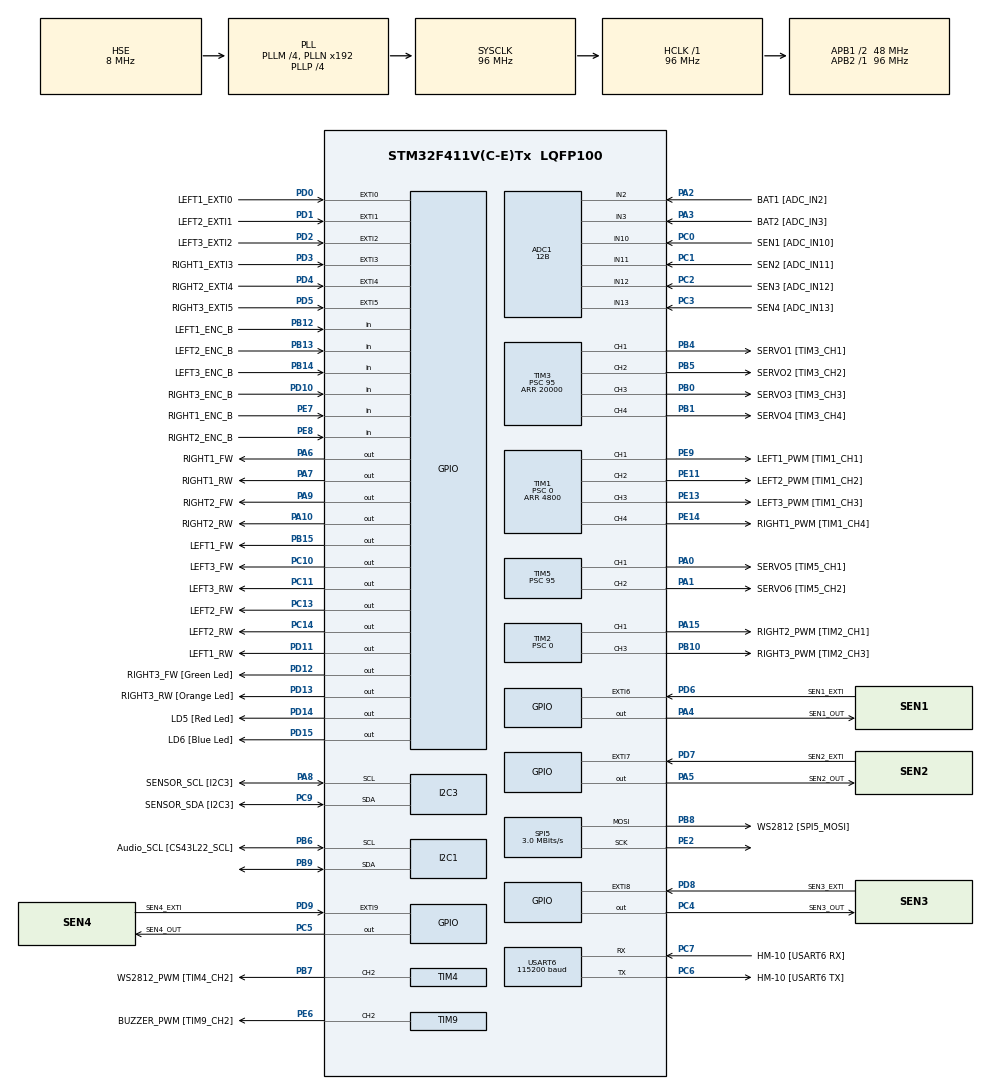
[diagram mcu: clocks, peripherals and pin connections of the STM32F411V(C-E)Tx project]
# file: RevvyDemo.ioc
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ADC1.Channel-4\#ChannelRegularConversion=ADC_CHANNEL_2
ADC1.Channel-5\#ChannelRegularConversion=ADC_CHANNEL_3
ADC1.Channel-6\#ChannelRegularConversion=ADC_CHANNEL_10
ADC1.Channel-7\#ChannelRegularConversion=ADC_CHANNEL_11
ADC1.Channel-8\#ChannelRegularConversion=ADC_CHANNEL_12
ADC1.Channel-9\#ChannelRegularConversion=ADC_CHANNEL_13
ADC1.ClockPrescaler=ADC_CLOCK_SYNC_PCLK_DIV4
ADC1.ContinuousConvMode=ENABLE
ADC1.DMAContinuousRequests=ENABLE
ADC1.DataAlign=ADC_DATAALIGN_RIGHT
ADC1.DiscontinuousConvMode=DISABLE
ADC1.EOCSelection=ADC_EOC_SINGLE_CONV
ADC1.EnableAnalogWatchDog=false
ADC1.ExternalTrigConv=ADC_SOFTWARE_START
ADC1.ExternalTrigConvEdge=ADC_EXTERNALTRIGCONVEDGE_NONE
ADC1.InjNumberOfConversion=0
ADC1.NbrOfConversion=6
ADC1.NbrOfConversionFlag=1
ADC1.Rank-4\#ChannelRegularConversion=1
ADC1.Rank-5\#ChannelRegularConversion=2
ADC1.Rank-6\#ChannelRegularConversion=3
ADC1.Rank-7\#ChannelRegularConversion=4
ADC1.Rank-8\#ChannelRegularConversion=5
ADC1.Rank-9\#ChannelRegularConversion=6
ADC1.Resolution=ADC_RESOLUTION_12B
ADC1.SamplingTime-4\#ChannelRegularConversion=ADC_SAMPLETIME_480CYCLES
ADC1.SamplingTime-5\#ChannelRegularConversion=ADC_SAMPLETIME_480CYCLES
ADC1.SamplingTime-6\#ChannelRegularConversion=ADC_SAMPLETIME_480CYCLES
ADC1.SamplingTime-7\#ChannelRegularConversion=ADC_SAMPLETIME_480CYCLES
ADC1.SamplingTime-8\#ChannelRegularConversion=ADC_SAMPLETIME_480CYCLES
ADC1.SamplingTime-9\#ChannelRegularConversion=ADC_SAMPLETIME_480CYCLES
ADC1.ScanConvMode=ENABLE
ADC1.master=1
Dma.ADC1.0.Direction=DMA_PERIPH_TO_MEMORY
Dma.ADC1.0.FIFOMode=DMA_FIFOMODE_DISABLE
Dma.ADC1.0.Instance=DMA2_Stream4
Dma.ADC1.0.MemDataAlignment=DMA_MDATAALIGN_WORD
Dma.ADC1.0.MemInc=DMA_MINC_ENABLE
Dma.ADC1.0.Mode=DMA_CIRCULAR
Dma.ADC1.0.PeriphDataAlignment=DMA_PDATAALIGN_WORD
Dma.ADC1.0.PeriphInc=DMA_PINC_DISABLE
Dma.ADC1.0.Priority=DMA_PRIORITY_LOW
Dma.Request0=ADC1
Dma.Request1=TIM4_CH2
Dma.Request2=SPI5_TX
Dma.SPI5_TX.2.Direction=DMA_MEMORY_TO_PERIPH
Dma.SPI5_TX.2.FIFOMode=DMA_FIFOMODE_DISABLE
Dma.SPI5_TX.2.Instance=DMA2_Stream5
Dma.SPI5_TX.2.MemDataAlignment=DMA_MDATAALIGN_BYTE
Dma.SPI5_TX.2.MemInc=DMA_MINC_ENABLE
Dma.SPI5_TX.2.Mode=DMA_NORMAL
Dma.SPI5_TX.2.PeriphDataAlignment=DMA_PDATAALIGN_BYTE
Dma.SPI5_TX.2.PeriphInc=DMA_PINC_DISABLE
Dma.SPI5_TX.2.Priority=DMA_PRIORITY_HIGH
Dma.TIM4_CH2.1.Direction=DMA_MEMORY_TO_PERIPH
Dma.TIM4_CH2.1.FIFOMode=DMA_FIFOMODE_ENABLE
Dma.TIM4_CH2.1.FIFOThreshold=DMA_FIFO_THRESHOLD_FULL
Dma.TIM4_CH2.1.Instance=DMA1_Stream3
Dma.TIM4_CH2.1.MemBurst=DMA_MBURST_INC4
Dma.TIM4_CH2.1.MemDataAlignment=DMA_MDATAALIGN_HALFWORD
Dma.TIM4_CH2.1.MemInc=DMA_MINC_ENABLE
Dma.TIM4_CH2.1.Mode=DMA_NORMAL
Dma.TIM4_CH2.1.PeriphBurst=DMA_PBURST_SINGLE
Dma.TIM4_CH2.1.PeriphDataAlignment=DMA_PDATAALIGN_HALFWORD
Dma.TIM4_CH2.1.PeriphInc=DMA_PINC_DISABLE
Dma.TIM4_CH2.1.Priority=DMA_PRIORITY_HIGH
FREERTOS.Tasks01=defaultTask,-3,128,StartDefaultTask,Default,NULL,Dynamic,NULL,NULL;sensorTask,0,128,StartSensorTask,Default,NULL,Dynamic,NULL,NULL;controlTask,2,128,StartControlTask,Default,NULL,Dynamic,NULL,NULL;commTask,1,128,StartCommTask,Default,NULL,Dynamic,NULL,NULL;idleTask,-2,128,StartIdleTask,Default,NULL,Dynamic,NULL,NULL;ledTask,0,128,StartLedTask,Default,NULL,Dynamic,NULL,NULL;applicationTask,0,128,StartApplicationTask,Default,NULL,Dynamic,NULL,NULL
Mcu.Family=STM32F4
Mcu.Name=STM32F411V(C-E)Tx
Mcu.Package=LQFP100
NVIC.DMA1_Stream3_IRQn=true\:5\:0\:false\:false\:true\:true\:false
NVIC.DMA2_Stream4_IRQn=true\:5\:0\:false\:false\:true\:true\:false
NVIC.DMA2_Stream5_IRQn=true\:5\:0\:false\:false\:true\:true\:false
NVIC.EXTI0_IRQn=true\:5\:0\:false\:false\:true\:true\:true
NVIC.EXTI1_IRQn=true\:5\:0\:false\:false\:true\:true\:true
NVIC.EXTI2_IRQn=true\:5\:0\:false\:false\:true\:true\:true
NVIC.EXTI3_IRQn=true\:5\:0\:false\:false\:true\:true\:true
NVIC.EXTI4_IRQn=true\:5\:0\:false\:false\:true\:true\:true
NVIC.EXTI9_5_IRQn=true\:5\:0\:false\:false\:true\:true\:true
NVIC.PriorityGroup=NVIC_PRIORITYGROUP_4
NVIC.TIM1_TRG_COM_TIM11_IRQn=true\:0\:0\:false\:false\:true\:false\:false
NVIC.TimeBase=TIM1_TRG_COM_TIM11_IRQn
NVIC.TimeBaseIP=TIM11
NVIC.USART6_IRQn=true\:5\:0\:false\:false\:true\:true\:true
PA0-WKUP.GPIO_Label=SERVO5 [TIM5_CH1]
PA0-WKUP.Signal=S_TIM5_CH1
PA1.GPIO_Label=SERVO6 [TIM5_CH2]
PA1.Signal=S_TIM5_CH2
PA10.GPIO_Label=RIGHT2_RW
PA10.Signal=GPIO_Output
PA13.GPIO_Label=SWDIO
PA13.Mode=Serial_Wire
PA13.Signal=SYS_JTMS-SWDIO
PA14.GPIO_Label=SWCLK
PA14.Mode=Serial_Wire
PA14.Signal=SYS_JTCK-SWCLK
PA15.GPIO_Label=RIGHT2_PWM [TIM2_CH1]
PA15.Signal=S_TIM2_CH1_ETR
PA2.GPIO_Label=BAT1 [ADC_IN2]
PA2.Signal=ADCx_IN2
PA3.GPIO_Label=BAT2 [ADC_IN3]
PA3.Signal=ADCx_IN3
PA4.GPIO_Label=SEN1_OUT
PA4.Signal=GPIO_Output
PA5.GPIO_Label=SEN2_OUT
PA5.Signal=GPIO_Output
PA6.GPIO_Label=RIGHT1_FW
PA6.Signal=GPIO_Output
PA7.GPIO_Label=RIGHT1_RW
PA7.Signal=GPIO_Output
PA8.GPIO_Label=SENSOR_SCL [I2C3]
PA8.Mode=I2C
PA8.Signal=I2C3_SCL
PA9.GPIO_Label=RIGHT2_FW
PA9.Signal=GPIO_Output
PB0.GPIO_Label=SERVO3 [TIM3_CH3]
PB0.Signal=S_TIM3_CH3
PB1.GPIO_Label=SERVO4 [TIM3_CH4]
PB1.Signal=S_TIM3_CH4
PB10.GPIO_Label=RIGHT3_PWM [TIM2_CH3]
PB10.Signal=S_TIM2_CH3
PB12.GPIO_Label=LEFT1_ENC_B
PB12.GPIO_PuPd=GPIO_PULLDOWN
PB12.Signal=GPIO_Input
PB13.GPIO_Label=LEFT2_ENC_B
PB13.GPIO_PuPd=GPIO_PULLDOWN
PB13.Signal=GPIO_Input
PB14.GPIO_Label=LEFT3_ENC_B
PB14.GPIO_PuPd=GPIO_PULLDOWN
PB14.Signal=GPIO_Input
PB15.GPIO_Label=LEFT1_FW
PB15.Signal=GPIO_Output
PB3.GPIO_Label=SWO
PB3.Signal=SYS_JTDO-SWO
PB4.GPIO_Label=SERVO1 [TIM3_CH1]
PB4.Signal=S_TIM3_CH1
PB5.GPIO_Label=SERVO2 [TIM3_CH2]
PB5.Signal=S_TIM3_CH2
PB6.GPIO_Label=Audio_SCL [CS43L22_SCL]
PB6.GPIO_Mode=GPIO_MODE_AF_OD
PB6.GPIO_PuPd=GPIO_NOPULL
PB6.GPIO_Speed=GPIO_SPEED_FREQ_LOW
PB6.Mode=I2C
PB6.Signal=I2C1_SCL
PB7.GPIO_Label=WS2812_PWM [TIM4_CH2]
PB7.GPIO_Speed=GPIO_SPEED_FREQ_HIGH
PB7.Signal=S_TIM4_CH2
PB8.GPIO_Label=WS2812 [SPI5_MOSI]
PB8.Mode=TX_Only_Simplex_Unidirect_Master
PB8.Signal=SPI5_MOSI
PB9.Mode=I2C
PB9.Signal=I2C1_SDA
PC0.GPIO_Label=SEN1 [ADC_IN10]
PC0.Signal=ADCx_IN10
PC1.GPIO_Label=SEN2 [ADC_IN11]
PC1.Signal=ADCx_IN11
PC10.GPIO_Label=LEFT3_FW
PC10.Signal=GPIO_Output
PC11.GPIO_Label=LEFT3_RW
PC11.Signal=GPIO_Output
PC13-ANTI_TAMP.GPIO_Label=LEFT2_FW
PC13-ANTI_TAMP.Signal=GPIO_Output
PC14-OSC32_IN.GPIO_Label=LEFT2_RW
PC14-OSC32_IN.Signal=GPIO_Output
PC2.GPIO_Label=SEN3 [ADC_IN12]
PC2.Signal=ADCx_IN12
PC3.GPIO_Label=SEN4 [ADC_IN13]
PC3.Signal=ADCx_IN13
PC4.GPIO_Label=SEN3_OUT
PC4.Signal=GPIO_Output
PC5.GPIO_Label=SEN4_OUT
PC5.Signal=GPIO_Output
PC6.GPIO_Label=HM-10 [USART6 TX]
PC6.Mode=Asynchronous
PC6.Signal=USART6_TX
PC7.GPIO_Label=HM-10 [USART6 RX]
PC7.Mode=Asynchronous
PC7.Signal=USART6_RX
PC9.GPIO_Label=SENSOR_SDA [I2C3]
PC9.Mode=I2C
PC9.Signal=I2C3_SDA
PD0.GPIO_Label=LEFT1_EXTI0
PD0.GPIO_ModeDefaultEXTI=GPIO_MODE_IT_RISING
PD0.GPIO_PuPd=GPIO_PULLDOWN
PD0.Signal=GPXTI0
PD1.GPIO_Label=LEFT2_EXTI1
PD1.GPIO_ModeDefaultEXTI=GPIO_MODE_IT_RISING
PD1.GPIO_PuPd=GPIO_PULLDOWN
PD1.Signal=GPXTI1
PD10.GPIO_Label=RIGHT3_ENC_B
PD10.GPIO_PuPd=GPIO_PULLDOWN
PD10.Signal=GPIO_Input
PD11.GPIO_Label=LEFT1_RW
PD11.Signal=GPIO_Output
PD12.GPIO_Label=RIGHT3_FW [Green Led]
PD12.GPIO_PuPd=GPIO_NOPULL
PD12.GPIO_Speed=GPIO_SPEED_FREQ_LOW
PD12.Signal=GPIO_Output
PD13.GPIO_Label=RIGHT3_RW [Orange Led]
PD13.GPIO_PuPd=GPIO_NOPULL
PD13.GPIO_Speed=GPIO_SPEED_FREQ_LOW
PD13.Signal=GPIO_Output
PD14.GPIO_Label=LD5 [Red Led]
PD14.GPIO_PuPd=GPIO_NOPULL
PD14.GPIO_Speed=GPIO_SPEED_FREQ_LOW
PD14.Signal=GPIO_Output
PD15.GPIO_Label=LD6 [Blue Led]
PD15.GPIO_PuPd=GPIO_NOPULL
PD15.GPIO_Speed=GPIO_SPEED_FREQ_LOW
PD15.Signal=GPIO_Output
PD2.GPIO_Label=LEFT3_EXTI2
PD2.GPIO_ModeDefaultEXTI=GPIO_MODE_IT_RISING
PD2.GPIO_PuPd=GPIO_PULLDOWN
PD2.Signal=GPXTI2
PD3.GPIO_Label=RIGHT1_EXTI3
PD3.GPIO_ModeDefaultEXTI=GPIO_MODE_IT_RISING
PD3.GPIO_PuPd=GPIO_PULLDOWN
PD3.Signal=GPXTI3
PD4.GPIO_Label=RIGHT2_EXTI4
PD4.GPIO_ModeDefaultEXTI=GPIO_MODE_IT_RISING
PD4.GPIO_PuPd=GPIO_PULLDOWN
PD4.Signal=GPXTI4
PD5.GPIO_Label=RIGHT3_EXTI5
PD5.GPIO_ModeDefaultEXTI=GPIO_MODE_IT_RISING
PD5.GPIO_PuPd=GPIO_PULLDOWN
PD5.Signal=GPXTI5
PD6.GPIO_Label=SEN1_EXTI
PD6.GPIO_ModeDefaultEXTI=GPIO_MODE_IT_RISING_FALLING
PD6.GPIO_PuPd=GPIO_PULLDOWN
PD6.Signal=GPXTI6
PD7.GPIO_Label=SEN2_EXTI
PD7.GPIO_ModeDefaultEXTI=GPIO_MODE_IT_RISING_FALLING
PD7.GPIO_PuPd=GPIO_PULLDOWN
PD7.Signal=GPXTI7
PD8.GPIO_Label=SEN3_EXTI
PD8.GPIO_ModeDefaultEXTI=GPIO_MODE_IT_RISING_FALLING
PD8.GPIO_PuPd=GPIO_PULLDOWN
PD8.Signal=GPXTI8
PD9.GPIO_Label=SEN4_EXTI
PD9.GPIO_ModeDefaultEXTI=GPIO_MODE_IT_RISING_FALLING
PD9.GPIO_PuPd=GPIO_PULLDOWN
PD9.Signal=GPXTI9
PE11.GPIO_Label=LEFT2_PWM [TIM1_CH2]
PE11.Signal=S_TIM1_CH2
PE13.GPIO_Label=LEFT3_PWM [TIM1_CH3]
PE13.Signal=S_TIM1_CH3
PE14.GPIO_Label=RIGHT1_PWM [TIM1_CH4]
PE14.Signal=S_TIM1_CH4
PE2.Mode=TX_Only_Simplex_Unidirect_Master
PE2.Signal=SPI5_SCK
PE6.GPIO_Label=BUZZER_PWM [TIM9_CH2]
PE6.Signal=S_TIM9_CH2
PE7.GPIO_Label=RIGHT1_ENC_B
PE7.GPIO_PuPd=GPIO_PULLDOWN
PE7.Signal=GPIO_Input
PE8.GPIO_Label=RIGHT2_ENC_B
PE8.GPIO_PuPd=GPIO_PULLDOWN
PE8.Signal=GPIO_Input
PE9.GPIO_Label=LEFT1_PWM [TIM1_CH1]
PE9.Signal=S_TIM1_CH1
PH0\ -\ OSC_IN.GPIO_Label=PH0-OSC_IN
PH0\ -\ OSC_IN.Mode=HSE-External-Oscillator
PH0\ -\ OSC_IN.Signal=RCC_OSC_IN
PH1\ -\ OSC_OUT.GPIO_Label=PH1-OSC_OUT
PH1\ -\ OSC_OUT.Mode=HSE-External-Oscillator
PH1\ -\ OSC_OUT.Signal=RCC_OSC_OUT
ProjectManager.HeapSize=0x200
ProjectManager.StackSize=0x400
ProjectManager.TargetToolchain=EWARM V8
RCC.48MHZClocksFreq_Value=48000000
RCC.AHBFreq_Value=96000000
RCC.APB1CLKDivider=RCC_HCLK_DIV2
RCC.APB1Freq_Value=48000000
RCC.APB1TimFreq_Value=96000000
RCC.APB2Freq_Value=96000000
RCC.APB2TimFreq_Value=96000000
RCC.CortexFreq_Value=96000000
RCC.HCLKFreq_Value=96000000
RCC.HSE_VALUE=8000000
RCC.HSI_VALUE=16000000
RCC.LSE_VALUE=32768
RCC.PLLI2SM=5
RCC.PLLI2SN=200
RCC.PLLM=4
RCC.PLLP=RCC_PLLP_DIV4
RCC.PLLQ=8
RCC.PLLSourceVirtual=RCC_PLLSOURCE_HSE
RCC.SYSCLKFreq_VALUE=96000000
RCC.SYSCLKSource=RCC_SYSCLKSOURCE_PLLCLK
RCC.VCOOutputFreq_Value=384000000
SH.ADCx_IN10.0=ADC1_IN10,IN10
SH.ADCx_IN11.0=ADC1_IN11,IN11
SH.ADCx_IN12.0=ADC1_IN12,IN12
SH.ADCx_IN13.0=ADC1_IN13,IN13
SH.ADCx_IN2.0=ADC1_IN2,IN2
SH.ADCx_IN3.0=ADC1_IN3,IN3
SH.S_TIM1_CH1.0=TIM1_CH1,PWM Generation1 CH1
SH.S_TIM1_CH2.0=TIM1_CH2,PWM Generation2 CH2
SH.S_TIM1_CH3.0=TIM1_CH3,PWM Generation3 CH3
SH.S_TIM1_CH4.0=TIM1_CH4,PWM Generation4 CH4
SH.S_TIM2_CH1_ETR.0=TIM2_CH1,PWM Generation1 CH1
SH.S_TIM2_CH3.0=TIM2_CH3,PWM Generation3 CH3
SH.S_TIM3_CH1.0=TIM3_CH1,PWM Generation1 CH1
SH.S_TIM3_CH2.0=TIM3_CH2,PWM Generation2 CH2
SH.S_TIM3_CH3.0=TIM3_CH3,PWM Generation3 CH3
SH.S_TIM3_CH4.0=TIM3_CH4,PWM Generation4 CH4
SH.S_TIM4_CH2.0=TIM4_CH2,PWM Generation2 CH2
SH.S_TIM5_CH1.0=TIM5_CH1,PWM Generation1 CH1
SH.S_TIM5_CH2.0=TIM5_CH2,PWM Generation2 CH2
SH.S_TIM9_CH2.0=TIM9_CH2,PWM Generation2 CH2
SPI5.BaudRatePrescaler=SPI_BAUDRATEPRESCALER_32
SPI5.CalculateBaudRate=3.0 MBits/s
SPI5.DataSize=SPI_DATASIZE_8BIT
SPI5.Direction=SPI_DIRECTION_2LINES
SPI5.Mode=SPI_MODE_MASTER
SPI5.VirtualType=VM_MASTER
TIM1.Channel-PWM\ Generation1\ CH1=TIM_CHANNEL_1
TIM1.Channel-PWM\ Generation2\ CH2=TIM_CHANNEL_2
TIM1.Channel-PWM\ Generation3\ CH3=TIM_CHANNEL_3
TIM1.Channel-PWM\ Generation4\ CH4=TIM_CHANNEL_4
TIM1.Period=4800
TIM1.Prescaler=0
TIM10.ClockDivision=TIM_CLOCKDIVISION_DIV1
TIM10.Period=65535
TIM10.Prescaler=960
TIM2.Channel-PWM\ Generation1\ CH1=TIM_CHANNEL_1
TIM2.Channel-PWM\ Generation3\ CH3=TIM_CHANNEL_3
TIM2.Period=4800
TIM2.Prescaler=0
TIM3.Channel-PWM\ Generation1\ CH1=TIM_CHANNEL_1
TIM3.Channel-PWM\ Generation2\ CH2=TIM_CHANNEL_2
TIM3.Channel-PWM\ Generation3\ CH3=TIM_CHANNEL_3
TIM3.Channel-PWM\ Generation4\ CH4=TIM_CHANNEL_4
TIM3.Period=20000
TIM3.Prescaler=95
TIM4.Channel-PWM\ Generation2\ CH2=TIM_CHANNEL_2
TIM4.Period=119
TIM4.Prescaler=0
TIM5.Channel-PWM\ Generation1\ CH1=TIM_CHANNEL_1
TIM5.Channel-PWM\ Generation2\ CH2=TIM_CHANNEL_2
TIM5.Period=20000
TIM5.Prescaler=95
TIM9.Channel-PWM\ Generation2\ CH2=TIM_CHANNEL_2
TIM9.Period=2400
USART6.BaudRate=115200
USART6.VirtualMode=VM_ASYNC
VP_CRC_VS_CRC.Mode=CRC_Activate
VP_FREERTOS_VS_ENABLE.Mode=Enabled
VP_SYS_VS_tim11.Mode=TIM11
VP_TIM10_VS_ClockSourceINT.Mode=Enable_Timer
board=32F411EDISCOVERY

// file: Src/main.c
/* USER CODE BEGIN Header */
/**
  * @brief  Function implementing the defaultTask thread.
  * @param  argument: Not used
  * @retval None
  */
/* USER CODE END Header */

#include "main.h"
#include "cmsis_os.h"

/* USER CODE BEGIN Includes */
#include <math.h>
#include <stdlib.h>
#include "WS2812_Lib.h"
#include "stm32f411e_discovery.h"
#include "stm32f411e_discovery_accelerometer.h"
/* USER CODE END Includes */

ADC_HandleTypeDef hadc1;
DMA_HandleTypeDef hdma_adc1;

CRC_HandleTypeDef hcrc;

I2C_HandleTypeDef hi2c1;
I2C_HandleTypeDef hi2c3;

SPI_HandleTypeDef hspi5;
DMA_HandleTypeDef hdma_spi5_tx;

TIM_HandleTypeDef htim1;
TIM_HandleTypeDef htim2;
TIM_HandleTypeDef htim3;
TIM_HandleTypeDef htim4;
TIM_HandleTypeDef htim5;
TIM_HandleTypeDef htim9;
TIM_HandleTypeDef htim10;
DMA_HandleTypeDef hdma_tim4_ch2;

UART_HandleTypeDef huart6;

osThreadId defaultTaskHandle;
osThreadId sensorTaskHandle;
osThreadId controlTaskHandle;
osThreadId commTaskHandle;
osThreadId idleTaskHandle;
osThreadId ledTaskHandle;
osThreadId applicationTaskHandle;
/* USER CODE BEGIN PV */
/* Private variables ---------------------------------------------------------*/
#define ABS(x)         (x < 0) ? (-x) : x
#define PI     3.14159

#define COMPASS_X_MAX 702
#define COMPASS_X_MIN -358
#define COMPASS_Y_MAX 293
#define COMPASS_Y_MIN -829
#define COMPASS_Z_MAX 845
#define COMPASS_Z_MIN -282

#define NORMALVOLTAGE_MOT 1.4
#define LOWVOLTAGE_MOT 1.18

#define NORMALVOLTAGE_LOGIC 1.1
#define LOWVOLTAGE_LOGIC 0.8

static volatile uint32_t ADC_Buf[6];
static volatile uint32_t ADC_Values[6];

static uint16_t mot1Cntr, mot1CntrPrev = 0; //L1
static uint16_t mot2Cntr, mot2CntrPrev = 0; //L2
static uint16_t mot3Cntr, mot3CntrPrev = 0; //L3
static uint16_t mot4Cntr, mot4CntrPrev = 0; //R1
static uint16_t mot5Cntr, mot5CntrPrev = 0; //R2
static uint16_t mot6Cntr, mot6CntrPrev = 0; //R3
static volatile uint8_t mot1Dir = 0; //L1
static volatile uint8_t mot2Dir = 0; //L2
static volatile uint8_t mot3Dir = 0; //L3
static volatile uint8_t mot4Dir = 0; //R1
static volatile uint8_t mot5Dir = 0; //R2
static volatile uint8_t mot6Dir = 0; //R3

static volatile uint32_t sen1Cntr, sen1Start, sen1End, sen1Length = 0; //Sensors
static volatile uint32_t sen2Cntr, sen2Start, sen2End, sen2Length = 0; //Sensors
static volatile uint32_t sen3Cntr, sen3Start, sen3End, sen3Length = 0; //Sensors
static volatile uint32_t sen4Cntr, sen4Start, sen4End, sen4Length = 0; //Sensors
static volatile float sen1Distance, sen1DistanceFiltered, sen1DistancePrev = 0;
static volatile float sen2Distance, sen2DistanceFiltered, sen2DistancePrev = 0;
static volatile float sen3Distance, sen3DistanceFiltered, sen3DistancePrev = 0;
static volatile float sen4Distance, sen4DistanceFiltered, sen4DistancePrev = 0;

static volatile uint16_t sen1DebounceCounter = 1000;
static volatile uint16_t sen2DebounceCounter = 1000;
static volatile uint16_t sen3DebounceCounter = 1000;
static volatile uint16_t sen4DebounceCounter = 1000;

static volatile float batteryVoltage1 = 0;
static volatile float batteryVoltage2 = 0;

static volatile uint16_t sen1AnalogValue = 0;
static volatile uint16_t sen2AnalogValue = 0;
static volatile uint16_t sen3AnalogValue = 0;
static volatile uint16_t sen4AnalogValue = 0;

static volatile uint32_t internalCounter = 0;

static volatile float roll,pitch,heading = 0;
static volatile float fNormAcc,fSinRoll,fCosRoll,fSinPitch,fCosPitch = 0.0f;
static volatile float accX,accY,accZ = 0;
static volatile float accXFiltered,accYFiltered,accZFiltered = 0;
static volatile float compassX,compassY,compassZ = 0;

static volatile float wheelL1Odometer_m, wheelL1Odometer_m_prev = 0;
static volatile float wheelL2Odometer_m, wheelL2Odometer_m_prev = 0;
static volatile float wheelL3Odometer_m, wheelL3Odometer_m_prev = 0;
static volatile float wheelR1Odometer_m, wheelR1Odometer_m_prev = 0;
static volatile float wheelR2Odometer_m, wheelR2Odometer_m_prev = 0;
static volatile float wheelR3Odometer_m, wheelR3Odometer_m_prev = 0;
static volatile float wheelL1Angle_deg = 0;
static volatile float wheelL2Angle_deg = 0;
static volatile float wheelL3Angle_deg = 0;
static volatile float wheelR1Angle_deg = 0;
static volatile float wheelR2Angle_deg = 0;
static volatile float wheelR3Angle_deg = 0;

static volatile float wheelL1RawVelocity_mps, wheelL1FiltVelocity_mps, wheelL1FiltVelocity_rpm = 0;
static volatile float wheelL2RawVelocity_mps, wheelL2FiltVelocity_mps, wheelL2FiltVelocity_rpm = 0;
static volatile float wheelL3RawVelocity_mps, wheelL3FiltVelocity_mps, wheelL3FiltVelocity_rpm = 0;
static volatile float wheelR1RawVelocity_mps, wheelR1FiltVelocity_mps, wheelR1FiltVelocity_rpm = 0;
static volatile float wheelR2RawVelocity_mps, wheelR2FiltVelocity_mps, wheelR2FiltVelocity_rpm = 0;
static volatile float wheelR3RawVelocity_mps, wheelR3FiltVelocity_mps, wheelR3FiltVelocity_rpm = 0;

static volatile float wheelSize_m = 0.20; // 20cm circumference
//static volatile uint16_t encoderSignalsPerRound = 360; // 3 counts per motor round and a 120:1 gearbox
static volatile uint16_t encoderSignalsPerRound = 144; // 3 counts per motor round and a 48:1 gearbox
static volatile uint16_t speedSensingTaskCycle_ms = 10; // 10ms task cycle time
//static volatile float maxVelocity = 0.15; // for the 120:1 gears!
static volatile float maxVelocity = 0.5; // for the 48:1 gears!

static volatile float referenceSpeedLeft = 0;
static volatile float referenceSpeedRight = 0;

static volatile uint32_t timeStamp =0;
static volatile uint32_t timeOutGuard, timeOutGuardMax =0;
static uint8_t receiveBuffer[10]={0};
static volatile float referenceSpeed = 0;
static volatile float referenceAngle = 0;
static uint8_t messageCounter, messageCounterPrev = 0;
static volatile uint8_t buttonState = 0;

static volatile float nextSpeedLeft, nextSpeedRight = 0;
static volatile float reqSpeedLeft, reqSpeedRight, currSpeedLeft, currSpeedRight = 0;
static volatile float speedRampRate = 0.05;

static volatile float wheelL1VelocityError, wheelL1VelocityErrorBefore, wheelL1VelocityIntError, wheelL1VelocityDerivatedError, wheelL1SumControl, wheelL1SumControlBeforeSaturation = 0;
static volatile float wheelL2VelocityError, wheelL2VelocityErrorBefore, wheelL2VelocityIntError, wheelL2VelocityDerivatedError, wheelL2SumControl, wheelL2SumControlBeforeSaturation = 0;
static volatile float wheelL3VelocityError, wheelL3VelocityErrorBefore, wheelL3VelocityIntError, wheelL3VelocityDerivatedError, wheelL3SumControl, wheelL3SumControlBeforeSaturation = 0;
static volatile float wheelR1VelocityError, wheelR1VelocityErrorBefore, wheelR1VelocityIntError, wheelR1VelocityDerivatedError, wheelR1SumControl, wheelR1SumControlBeforeSaturation = 0;
static volatile float wheelR2VelocityError, wheelR2VelocityErrorBefore, wheelR2VelocityIntError, wheelR2VelocityDerivatedError, wheelR2SumControl, wheelR2SumControlBeforeSaturation = 0;
static volatile float wheelR3VelocityError, wheelR3VelocityErrorBefore, wheelR3VelocityIntError, wheelR3VelocityDerivatedError, wheelR3SumControl, wheelR3SumControlBeforeSaturation = 0;

static volatile float maxDutyCycle = 100;
static volatile float antiWindup = 0.01;//0.004;
static volatile float ctrlP = 400;//750;
static volatile float ctrlI = 8;//10;
static volatile float ctrlD = 2;

static volatile float positionErrorL3_deg = 0;
static volatile float referenceAngleL3_deg = 0;
static volatile float positionErrorR3_deg = 0;
static volatile float referenceAngleR3_deg = 0;
static volatile float ctrlP_pos = 0.004;
static volatile float angleIncrement = 0.5;

static volatile uint16_t ultrasonicDebounceLimit = 50;
static volatile uint8_t ultrasonicActive = 0;
static volatile uint8_t bumperActive = 0;
static volatile uint8_t autonomousActive = 0;
/* USER CODE END PV */

void SystemClock_Config(void);
static void MX_GPIO_Init(void);
static void MX_DMA_Init(void);
static void MX_TIM1_Init(void);
static void MX_TIM2_Init(void);
static void MX_I2C1_Init(void);
static void MX_ADC1_Init(void);
static void MX_CRC_Init(void);
static void MX_USART6_UART_Init(void);
static void MX_TIM3_Init(void);
static void MX_TIM4_Init(void);
static void MX_TIM5_Init(void);
static void MX_I2C3_Init(void);
static void MX_TIM9_Init(void);
static void MX_TIM10_Init(void);
static void MX_SPI5_Init(void);
void StartDefaultTask(void const * argument);
void StartSensorTask(void const * argument);
void StartControlTask(void const * argument);
void StartCommTask(void const * argument);
void StartIdleTask(void const * argument);
void StartLedTask(void const * argument);
void StartApplicationTask(void const * argument);

/* USER CODE BEGIN PFP */
/* Private function prototypes -----------------------------------------------*/

/* USER CODE END PFP */

/* USER CODE BEGIN 0 */
void HAL_ADC_ConvCpltCallback(ADC_HandleTypeDef* hadc){

  if(hadc->Instance==ADC1){
    ADC_Values[0] = ADC_Buf[0];
    ADC_Values[1] = ADC_Buf[1];
    ADC_Values[2] = ADC_Buf[2];
    ADC_Values[3] = ADC_Buf[3];
    ADC_Values[4] = ADC_Buf[4];
    ADC_Values[5] = ADC_Buf[5];
  }
}
/* USER CODE END 0 */

int main(void)
{

  /* MCU Configuration--------------------------------------------------------*/

  /* Reset of all peripherals, Initializes the Flash interface and the Systick. */
  HAL_Init();

  /* Configure the system clock */
  SystemClock_Config();

  /* Initialize all configured peripherals */
  MX_GPIO_Init();
  MX_DMA_Init();
  MX_TIM1_Init();
  MX_TIM2_Init();
  MX_I2C1_Init();
  MX_ADC1_Init();
  MX_CRC_Init();
  MX_USART6_UART_Init();
  MX_TIM3_Init();
  MX_TIM4_Init();
  MX_TIM5_Init();
  MX_I2C3_Init();
  MX_TIM9_Init();
  MX_TIM10_Init();
  MX_SPI5_Init();
  /* USER CODE BEGIN 2 */

  // 6*PWM signals for the 6 DC motors
  HAL_TIM_PWM_Start(&htim1, TIM_CHANNEL_1);
  HAL_TIMEx_PWMN_Start(&htim1, TIM_CHANNEL_1);
  HAL_TIM_PWM_Start(&htim1, TIM_CHANNEL_2);
  HAL_TIMEx_PWMN_Start(&htim1, TIM_CHANNEL_2);
  HAL_TIM_PWM_Start(&htim1, TIM_CHANNEL_3);
  HAL_TIMEx_PWMN_Start(&htim1, TIM_CHANNEL_3);
  HAL_TIM_PWM_Start(&htim1, TIM_CHANNEL_4);
  HAL_TIMEx_PWMN_Start(&htim1, TIM_CHANNEL_4);
  HAL_TIM_PWM_Start(&htim2, TIM_CHANNEL_1);
  HAL_TIMEx_PWMN_Start(&htim2, TIM_CHANNEL_1);
  HAL_TIM_PWM_Start(&htim2, TIM_CHANNEL_3);
  HAL_TIMEx_PWMN_Start(&htim2, TIM_CHANNEL_3);
  // 6*PWM signals for the 6 servos
  HAL_TIM_PWM_Start(&htim3, TIM_CHANNEL_1);
  HAL_TIMEx_PWMN_Start(&htim3, TIM_CHANNEL_1);
  HAL_TIM_PWM_Start(&htim3, TIM_CHANNEL_2);
  HAL_TIMEx_PWMN_Start(&htim3, TIM_CHANNEL_2);
  HAL_TIM_PWM_Start(&htim3, TIM_CHANNEL_3);
  HAL_TIMEx_PWMN_Start(&htim3, TIM_CHANNEL_3);
  HAL_TIM_PWM_Start(&htim3, TIM_CHANNEL_4);
  HAL_TIMEx_PWMN_Start(&htim3, TIM_CHANNEL_4);
  HAL_TIM_PWM_Start(&htim5, TIM_CHANNEL_1);
  HAL_TIMEx_PWMN_Start(&htim5, TIM_CHANNEL_1);
  HAL_TIM_PWM_Start(&htim5, TIM_CHANNEL_2);
  HAL_TIMEx_PWMN_Start(&htim5, TIM_CHANNEL_2);
  // 1*PWM signal for buzzer
  HAL_TIM_PWM_Start(&htim9, TIM_CHANNEL_2);
  HAL_TIMEx_PWMN_Start(&htim9, TIM_CHANNEL_2);

  //Start internal timer for 10us time measurement
  HAL_TIM_Base_Start(&htim10);

  // Test code START
  TIM1->CCR1 = 00*4800/100; //LEFT1
  TIM1->CCR2 = 00*4800/100; //LEFT2
  TIM1->CCR3 = 00*4800/100; //LEFT3
  TIM1->CCR4 = 00*4800/100; //RIGHT1
  TIM2->CCR1 = 00*4800/100; //RIGHT2
  TIM2->CCR3 = 00*4800/100; //RIGHT3

  TIM3->CCR1 = 5*20000/100; //SERVO1 - L1
  TIM3->CCR2 = 5*20000/100; //SERVO2 - L2
  TIM3->CCR3 = 5*20000/100; //SERVO3 - L3
  TIM3->CCR4 = 5*20000/100; //SERVO4 - L4
  TIM5->CCR1 = 5*20000/100; //SERVO5 - L5
  TIM5->CCR2 = 5*20000/100; //SERVO6 - L6

  TIM9->CCR2 = 0*2400/100; //Buzzer

  HAL_GPIO_WritePin(GPIOB, GPIO_PIN_15, GPIO_PIN_RESET); //LEFT1 FW
  HAL_GPIO_WritePin(GPIOD, GPIO_PIN_11, GPIO_PIN_SET); //LEFT1 RW
  HAL_GPIO_WritePin(GPIOC, GPIO_PIN_13, GPIO_PIN_RESET); //LEFT2 FW
  HAL_GPIO_WritePin(GPIOC, GPIO_PIN_14, GPIO_PIN_SET); //LEFT2 RW
  HAL_GPIO_WritePin(GPIOC, GPIO_PIN_10, GPIO_PIN_RESET); //LEFT3 FW
  HAL_GPIO_WritePin(GPIOC, GPIO_PIN_11, GPIO_PIN_SET); //LEFT3 RW
  HAL_GPIO_WritePin(GPIOA, GPIO_PIN_6,  GPIO_PIN_RESET); //RIGHT1 FW
  HAL_GPIO_WritePin(GPIOA, GPIO_PIN_7,  GPIO_PIN_SET); //RIGHT1 RW
  HAL_GPIO_WritePin(GPIOA, GPIO_PIN_9,  GPIO_PIN_RESET); //RIGHT2 FW
  HAL_GPIO_WritePin(GPIOA, GPIO_PIN_10, GPIO_PIN_SET); //RIGHT2 RW
  HAL_GPIO_WritePin(GPIOD, GPIO_PIN_12, GPIO_PIN_RESET); //RIGHT3 FW
  HAL_GPIO_WritePin(GPIOD, GPIO_PIN_13, GPIO_PIN_SET); //RIGHT3 RW
  HAL_GPIO_WritePin(GPIOA, GPIO_PIN_4,  GPIO_PIN_RESET); //SEN1 OUT
  HAL_GPIO_WritePin(GPIOA, GPIO_PIN_5,  GPIO_PIN_RESET); //SEN2 OUT
  HAL_GPIO_WritePin(GPIOC, GPIO_PIN_4,  GPIO_PIN_RESET); //SEN3 OUT
  HAL_GPIO_WritePin(GPIOC, GPIO_PIN_5,  GPIO_PIN_RESET); //SEN4 OUT
  // Test code END

  BSP_ACCELERO_Init();
  MAGNET_Init();

  /* USER CODE END 2 */

  /* Create the thread(s) */
  /* definition and creation of defaultTask */
  osThreadDef(defaultTask, StartDefaultTask, osPriorityIdle, 0, 128);
  defaultTaskHandle = osThreadCreate(osThread(defaultTask), NULL);

  /* definition and creation of sensorTask */
  osThreadDef(sensorTask, StartSensorTask, osPriorityNormal, 0, 128);
  sensorTaskHandle = osThreadCreate(osThread(sensorTask), NULL);

  /* definition and creation of controlTask */
  osThreadDef(controlTask, StartControlTask, osPriorityHigh, 0, 128);
  controlTaskHandle = osThreadCreate(osThread(controlTask), NULL);

  /* definition and creation of commTask */
  osThreadDef(commTask, StartCommTask, osPriorityAboveNormal, 0, 128);
  commTaskHandle = osThreadCreate(osThread(commTask), NULL);

  /* definition and creation of idleTask */
  osThreadDef(idleTask, StartIdleTask, osPriorityLow, 0, 128);
  idleTaskHandle = osThreadCreate(osThread(idleTask), NULL);

  /* definition and creation of ledTask */
  osThreadDef(ledTask, StartLedTask, osPriorityNormal, 0, 128);
  ledTaskHandle = osThreadCreate(osThread(ledTask), NULL);

  /* definition and creation of applicationTask */
  osThreadDef(applicationTask, StartApplicationTask, osPriorityNormal, 0, 128);
  applicationTaskHandle = osThreadCreate(osThread(applicationTask), NULL);

  /* Start scheduler */
  osKernelStart();

  /* We should never get here as control is now taken by the scheduler */

  /* Infinite loop */
  while (1)
  {

  }
}

void SystemClock_Config(void)
{
  RCC_OscInitTypeDef RCC_OscInitStruct = {0};
  RCC_ClkInitTypeDef RCC_ClkInitStruct = {0};

  /**Configure the main internal regulator output voltage
  */
  __HAL_RCC_PWR_CLK_ENABLE();
  __HAL_PWR_VOLTAGESCALING_CONFIG(PWR_REGULATOR_VOLTAGE_SCALE1);
  /**Initializes the CPU, AHB and APB busses clocks
  */
  RCC_OscInitStruct.OscillatorType = RCC_OSCILLATORTYPE_HSE;
  RCC_OscInitStruct.HSEState = RCC_HSE_ON;
  RCC_OscInitStruct.PLL.PLLState = RCC_PLL_ON;
  RCC_OscInitStruct.PLL.PLLSource = RCC_PLLSOURCE_HSE;
  RCC_OscInitStruct.PLL.PLLM = 4;
  RCC_OscInitStruct.PLL.PLLN = 192;
  RCC_OscInitStruct.PLL.PLLP = RCC_PLLP_DIV4;
  RCC_OscInitStruct.PLL.PLLQ = 8;
  if (HAL_RCC_OscConfig(&RCC_OscInitStruct) != HAL_OK)
  {
    Error_Handler();
  }
  /**Initializes the CPU, AHB and APB busses clocks
  */
  RCC_ClkInitStruct.ClockType = RCC_CLOCKTYPE_HCLK|RCC_CLOCKTYPE_SYSCLK
                              |RCC_CLOCKTYPE_PCLK1|RCC_CLOCKTYPE_PCLK2;
  RCC_ClkInitStruct.SYSCLKSource = RCC_SYSCLKSOURCE_PLLCLK;
  RCC_ClkInitStruct.AHBCLKDivider = RCC_SYSCLK_DIV1;
  RCC_ClkInitStruct.APB1CLKDivider = RCC_HCLK_DIV2;
  RCC_ClkInitStruct.APB2CLKDivider = RCC_HCLK_DIV1;

  if (HAL_RCC_ClockConfig(&RCC_ClkInitStruct, FLASH_LATENCY_3) != HAL_OK)
  {
    Error_Handler();
  }
}

static void MX_ADC1_Init(void)
{

  ADC_ChannelConfTypeDef sConfig = {0};

  /**Configure the global features of the ADC (Clock, Resolution, Data Alignment and number of conversion)
  */
  hadc1.Instance = ADC1;
  hadc1.Init.ClockPrescaler = ADC_CLOCK_SYNC_PCLK_DIV4;
  hadc1.Init.Resolution = ADC_RESOLUTION_12B;
  hadc1.Init.ScanConvMode = ENABLE;
  hadc1.Init.ContinuousConvMode = ENABLE;
  hadc1.Init.DiscontinuousConvMode = DISABLE;
  hadc1.Init.ExternalTrigConvEdge = ADC_EXTERNALTRIGCONVEDGE_NONE;
  hadc1.Init.ExternalTrigConv = ADC_SOFTWARE_START;
  hadc1.Init.DataAlign = ADC_DATAALIGN_RIGHT;
  hadc1.Init.NbrOfConversion = 6;
  hadc1.Init.DMAContinuousRequests = ENABLE;
  hadc1.Init.EOCSelection = ADC_EOC_SINGLE_CONV;
  if (HAL_ADC_Init(&hadc1) != HAL_OK)
  {
    Error_Handler();
  }
  /**Configure for the selected ADC regular channel its corresponding rank in the sequencer and its sample time.
  */
  sConfig.Channel = ADC_CHANNEL_2;
  sConfig.Rank = 1;
  sConfig.SamplingTime = ADC_SAMPLETIME_480CYCLES;
  if (HAL_ADC_ConfigChannel(&hadc1, &sConfig) != HAL_OK)
  {
    Error_Handler();
  }
  /**Configure for the selected ADC regular channel its corresponding rank in the sequencer and its sample time.
  */
  sConfig.Channel = ADC_CHANNEL_3;
  sConfig.Rank = 2;
  if (HAL_ADC_ConfigChannel(&hadc1, &sConfig) != HAL_OK)
  {
    Error_Handler();
  }
  /**Configure for the selected ADC regular channel its corresponding rank in the sequencer and its sample time.
  */
  sConfig.Channel = ADC_CHANNEL_10;
  sConfig.Rank = 3;
  if (HAL_ADC_ConfigChannel(&hadc1, &sConfig) != HAL_OK)
  {
    Error_Handler();
  }
  /**Configure for the selected ADC regular channel its corresponding rank in the sequencer and its sample time.
  */
  sConfig.Channel = ADC_CHANNEL_11;
  sConfig.Rank = 4;
  if (HAL_ADC_ConfigChannel(&hadc1, &sConfig) != HAL_OK)
  {
    Error_Handler();
  }
  /**Configure for the selected ADC regular channel its corresponding rank in the sequencer and its sample time.
  */
  sConfig.Channel = ADC_CHANNEL_12;
  sConfig.Rank = 5;
  if (HAL_ADC_ConfigChannel(&hadc1, &sConfig) != HAL_OK)
  {
    Error_Handler();
  }
  /**Configure for the selected ADC regular channel its corresponding rank in the sequencer and its sample time.
  */
  sConfig.Channel = ADC_CHANNEL_13;
  sConfig.Rank = 6;
  if (HAL_ADC_ConfigChannel(&hadc1, &sConfig) != HAL_OK)
  {
    Error_Handler();
  }

}

static void MX_CRC_Init(void)
{

  hcrc.Instance = CRC;
  if (HAL_CRC_Init(&hcrc) != HAL_OK)
  {
    Error_Handler();
  }

}

static void MX_I2C1_Init(void)
{

  hi2c1.Instance = I2C1;
  hi2c1.Init.ClockSpeed = 100000;
  hi2c1.Init.DutyCycle = I2C_DUTYCYCLE_2;
  hi2c1.Init.OwnAddress1 = 0;
  hi2c1.Init.AddressingMode = I2C_ADDRESSINGMODE_7BIT;
  hi2c1.Init.DualAddressMode = I2C_DUALADDRESS_DISABLE;
  hi2c1.Init.OwnAddress2 = 0;
  hi2c1.Init.GeneralCallMode = I2C_GENERALCALL_DISABLE;
  hi2c1.Init.NoStretchMode = I2C_NOSTRETCH_DISABLE;
  if (HAL_I2C_Init(&hi2c1) != HAL_OK)
  {
    Error_Handler();
  }

}

static void MX_I2C3_Init(void)
{

  hi2c3.Instance = I2C3;
  hi2c3.Init.ClockSpeed = 100000;
  hi2c3.Init.DutyCycle = I2C_DUTYCYCLE_2;
  hi2c3.Init.OwnAddress1 = 0;
  hi2c3.Init.AddressingMode = I2C_ADDRESSINGMODE_7BIT;
  hi2c3.Init.DualAddressMode = I2C_DUALADDRESS_DISABLE;
  hi2c3.Init.OwnAddress2 = 0;
  hi2c3.Init.GeneralCallMode = I2C_GENERALCALL_DISABLE;
  hi2c3.Init.NoStretchMode = I2C_NOSTRETCH_DISABLE;
  if (HAL_I2C_Init(&hi2c3) != HAL_OK)
  {
    Error_Handler();
  }

}

static void MX_SPI5_Init(void)
{

  /* SPI5 parameter configuration*/
  hspi5.Instance = SPI5;
  hspi5.Init.Mode = SPI_MODE_MASTER;
  hspi5.Init.Direction = SPI_DIRECTION_2LINES;
  hspi5.Init.DataSize = SPI_DATASIZE_8BIT;
  hspi5.Init.CLKPolarity = SPI_POLARITY_LOW;
  hspi5.Init.CLKPhase = SPI_PHASE_1EDGE;
  hspi5.Init.NSS = SPI_NSS_SOFT;
  hspi5.Init.BaudRatePrescaler = SPI_BAUDRATEPRESCALER_32;
  hspi5.Init.FirstBit = SPI_FIRSTBIT_MSB;
  hspi5.Init.TIMode = SPI_TIMODE_DISABLE;
  hspi5.Init.CRCCalculation = SPI_CRCCALCULATION_DISABLE;
  hspi5.Init.CRCPolynomial = 10;
  if (HAL_SPI_Init(&hspi5) != HAL_OK)
  {
    Error_Handler();
  }

}

static void MX_TIM1_Init(void)
{

  TIM_MasterConfigTypeDef sMasterConfig = {0};
  TIM_OC_InitTypeDef sConfigOC = {0};
  TIM_BreakDeadTimeConfigTypeDef sBreakDeadTimeConfig = {0};

  htim1.Instance = TIM1;
  htim1.Init.Prescaler = 0;
  htim1.Init.CounterMode = TIM_COUNTERMODE_UP;
  htim1.Init.Period = 4800;
  htim1.Init.ClockDivision = TIM_CLOCKDIVISION_DIV1;
  htim1.Init.RepetitionCounter = 0;
  if (HAL_TIM_PWM_Init(&htim1) != HAL_OK)
  {
    Error_Handler();
  }
  sMasterConfig.MasterOutputTrigger = TIM_TRGO_RESET;
  sMasterConfig.MasterSlaveMode = TIM_MASTERSLAVEMODE_DISABLE;
  if (HAL_TIMEx_MasterConfigSynchronization(&htim1, &sMasterConfig) != HAL_OK)
  {
    Error_Handler();
  }
  sConfigOC.OCMode = TIM_OCMODE_PWM1;
  sConfigOC.Pulse = 0;
  sConfigOC.OCPolarity = TIM_OCPOLARITY_HIGH;
  sConfigOC.OCNPolarity = TIM_OCNPOLARITY_HIGH;
  sConfigOC.OCFastMode = TIM_OCFAST_DISABLE;
  sConfigOC.OCIdleState = TIM_OCIDLESTATE_RESET;
  sConfigOC.OCNIdleState = TIM_OCNIDLESTATE_RESET;
  if (HAL_TIM_PWM_ConfigChannel(&htim1, &sConfigOC, TIM_CHANNEL_1) != HAL_OK)
  {
    Error_Handler();
  }
  if (HAL_TIM_PWM_ConfigChannel(&htim1, &sConfigOC, TIM_CHANNEL_2) != HAL_OK)
  {
    Error_Handler();
  }
  if (HAL_TIM_PWM_ConfigChannel(&htim1, &sConfigOC, TIM_CHANNEL_3) != HAL_OK)
  {
    Error_Handler();
  }
  if (HAL_TIM_PWM_ConfigChannel(&htim1, &sConfigOC, TIM_CHANNEL_4) != HAL_OK)
  {
    Error_Handler();
  }
  sBreakDeadTimeConfig.OffStateRunMode = TIM_OSSR_DISABLE;
  sBreakDeadTimeConfig.OffStateIDLEMode = TIM_OSSI_DISABLE;
  sBreakDeadTimeConfig.LockLevel = TIM_LOCKLEVEL_OFF;
  sBreakDeadTimeConfig.DeadTime = 0;
  sBreakDeadTimeConfig.BreakState = TIM_BREAK_DISABLE;
  sBreakDeadTimeConfig.BreakPolarity = TIM_BREAKPOLARITY_HIGH;
  sBreakDeadTimeConfig.AutomaticOutput = TIM_AUTOMATICOUTPUT_DISABLE;
  if (HAL_TIMEx_ConfigBreakDeadTime(&htim1, &sBreakDeadTimeConfig) != HAL_OK)
  {
    Error_Handler();
  }
  HAL_TIM_MspPostInit(&htim1);

}

static void MX_TIM2_Init(void)
{

  TIM_MasterConfigTypeDef sMasterConfig = {0};
  TIM_OC_InitTypeDef sConfigOC = {0};

  htim2.Instance = TIM2;
  htim2.Init.Prescaler = 0;
  htim2.Init.CounterMode = TIM_COUNTERMODE_UP;
  htim2.Init.Period = 4800;
  htim2.Init.ClockDivision = TIM_CLOCKDIVISION_DIV1;
  if (HAL_TIM_PWM_Init(&htim2) != HAL_OK)
  {
    Error_Handler();
  }
  sMasterConfig.MasterOutputTrigger = TIM_TRGO_RESET;
  sMasterConfig.MasterSlaveMode = TIM_MASTERSLAVEMODE_DISABLE;
  if (HAL_TIMEx_MasterConfigSynchronization(&htim2, &sMasterConfig) != HAL_OK)
  {
    Error_Handler();
  }
  sConfigOC.OCMode = TIM_OCMODE_PWM1;
  sConfigOC.Pulse = 0;
  sConfigOC.OCPolarity = TIM_OCPOLARITY_HIGH;
  sConfigOC.OCFastMode = TIM_OCFAST_DISABLE;
  if (HAL_TIM_PWM_ConfigChannel(&htim2, &sConfigOC, TIM_CHANNEL_1) != HAL_OK)
  {
    Error_Handler();
  }
  if (HAL_TIM_PWM_ConfigChannel(&htim2, &sConfigOC, TIM_CHANNEL_3) != HAL_OK)
  {
    Error_Handler();
  }
  HAL_TIM_MspPostInit(&htim2);

}

static void MX_TIM3_Init(void)
{

  TIM_MasterConfigTypeDef sMasterConfig = {0};
  TIM_OC_InitTypeDef sConfigOC = {0};

  htim3.Instance = TIM3;
  htim3.Init.Prescaler = 95;
  htim3.Init.CounterMode = TIM_COUNTERMODE_UP;
  htim3.Init.Period = 20000;
  htim3.Init.ClockDivision = TIM_CLOCKDIVISION_DIV1;
  if (HAL_TIM_PWM_Init(&htim3) != HAL_OK)
  {
    Error_Handler();
  }
  sMasterConfig.MasterOutputTrigger = TIM_TRGO_RESET;
  sMasterConfig.MasterSlaveMode = TIM_MASTERSLAVEMODE_DISABLE;
  if (HAL_TIMEx_MasterConfigSynchronization(&htim3, &sMasterConfig) != HAL_OK)
  {
    Error_Handler();
  }
  sConfigOC.OCMode = TIM_OCMODE_PWM1;
  sConfigOC.Pulse = 0;
  sConfigOC.OCPolarity = TIM_OCPOLARITY_HIGH;
  sConfigOC.OCFastMode = TIM_OCFAST_DISABLE;
  if (HAL_TIM_PWM_ConfigChannel(&htim3, &sConfigOC, TIM_CHANNEL_1) != HAL_OK)
  {
    Error_Handler();
  }
  if (HAL_TIM_PWM_ConfigChannel(&htim3, &sConfigOC, TIM_CHANNEL_2) != HAL_OK)
  {
    Error_Handler();
  }
  if (HAL_TIM_PWM_ConfigChannel(&htim3, &sConfigOC, TIM_CHANNEL_3) != HAL_OK)
  {
    Error_Handler();
  }
  if (HAL_TIM_PWM_ConfigChannel(&htim3, &sConfigOC, TIM_CHANNEL_4) != HAL_OK)
  {
    Error_Handler();
  }
  HAL_TIM_MspPostInit(&htim3);

}

static void MX_TIM4_Init(void)
{

  TIM_MasterConfigTypeDef sMasterConfig = {0};
  TIM_OC_InitTypeDef sConfigOC = {0};

  htim4.Instance = TIM4;
  htim4.Init.Prescaler = 0;
  htim4.Init.CounterMode = TIM_COUNTERMODE_UP;
  htim4.Init.Period = 119;
  htim4.Init.ClockDivision = TIM_CLOCKDIVISION_DIV1;
  if (HAL_TIM_PWM_Init(&htim4) != HAL_OK)
  {
    Error_Handler();
  }
  sMasterConfig.MasterOutputTrigger = TIM_TRGO_RESET;
  sMasterConfig.MasterSlaveMode = TIM_MASTERSLAVEMODE_DISABLE;
  if (HAL_TIMEx_MasterConfigSynchronization(&htim4, &sMasterConfig) != HAL_OK)
  {
    Error_Handler();
  }
  sConfigOC.OCMode = TIM_OCMODE_PWM1;
  sConfigOC.Pulse = 0;
  sConfigOC.OCPolarity = TIM_OCPOLARITY_HIGH;
  sConfigOC.OCFastMode = TIM_OCFAST_DISABLE;
  if (HAL_TIM_PWM_ConfigChannel(&htim4, &sConfigOC, TIM_CHANNEL_2) != HAL_OK)
  {
    Error_Handler();
  }
  HAL_TIM_MspPostInit(&htim4);

}

static void MX_TIM5_Init(void)
{

  TIM_MasterConfigTypeDef sMasterConfig = {0};
  TIM_OC_InitTypeDef sConfigOC = {0};

  htim5.Instance = TIM5;
  htim5.Init.Prescaler = 95;
  htim5.Init.CounterMode = TIM_COUNTERMODE_UP;
  htim5.Init.Period = 20000;
  htim5.Init.ClockDivision = TIM_CLOCKDIVISION_DIV1;
  if (HAL_TIM_PWM_Init(&htim5) != HAL_OK)
  {
    Error_Handler();
  }
  sMasterConfig.MasterOutputTrigger = TIM_TRGO_RESET;
  sMasterConfig.MasterSlaveMode = TIM_MASTERSLAVEMODE_DISABLE;
  if (HAL_TIMEx_MasterConfigSynchronization(&htim5, &sMasterConfig) != HAL_OK)
  {
    Error_Handler();
  }
  sConfigOC.OCMode = TIM_OCMODE_PWM1;
  sConfigOC.Pulse = 0;
  sConfigOC.OCPolarity = TIM_OCPOLARITY_HIGH;
  sConfigOC.OCFastMode = TIM_OCFAST_DISABLE;
  if (HAL_TIM_PWM_ConfigChannel(&htim5, &sConfigOC, TIM_CHANNEL_1) != HAL_OK)
  {
    Error_Handler();
  }
  if (HAL_TIM_PWM_ConfigChannel(&htim5, &sConfigOC, TIM_CHANNEL_2) != HAL_OK)
  {
    Error_Handler();
  }
  HAL_TIM_MspPostInit(&htim5);

}

static void MX_TIM9_Init(void)
{

  TIM_OC_InitTypeDef sConfigOC = {0};

  htim9.Instance = TIM9;
  htim9.Init.Prescaler = 0;
  htim9.Init.CounterMode = TIM_COUNTERMODE_UP;
  htim9.Init.Period = 2400;
  htim9.Init.ClockDivision = TIM_CLOCKDIVISION_DIV1;
  if (HAL_TIM_PWM_Init(&htim9) != HAL_OK)
  {
    Error_Handler();
  }
  sConfigOC.OCMode = TIM_OCMODE_PWM1;
  sConfigOC.Pulse = 0;
  sConfigOC.OCPolarity = TIM_OCPOLARITY_HIGH;
  sConfigOC.OCFastMode = TIM_OCFAST_DISABLE;
  if (HAL_TIM_PWM_ConfigChannel(&htim9, &sConfigOC, TIM_CHANNEL_2) != HAL_OK)
  {
    Error_Handler();
  }
  HAL_TIM_MspPostInit(&htim9);

}

static void MX_TIM10_Init(void)
{

  htim10.Instance = TIM10;
  htim10.Init.Prescaler = 960;
  htim10.Init.CounterMode = TIM_COUNTERMODE_UP;
  htim10.Init.Period = 65535;
  htim10.Init.ClockDivision = TIM_CLOCKDIVISION_DIV1;
  if (HAL_TIM_Base_Init(&htim10) != HAL_OK)
  {
    Error_Handler();
  }

}

static void MX_USART6_UART_Init(void)
{

  huart6.Instance = USART6;
  huart6.Init.BaudRate = 115200;
  huart6.Init.WordLength = UART_WORDLENGTH_8B;
  huart6.Init.StopBits = UART_STOPBITS_1;
  huart6.Init.Parity = UART_PARITY_NONE;
  huart6.Init.Mode = UART_MODE_TX_RX;
  huart6.Init.HwFlowCtl = UART_HWCONTROL_NONE;
  huart6.Init.OverSampling = UART_OVERSAMPLING_16;
  if (HAL_UART_Init(&huart6) != HAL_OK)
  {
    Error_Handler();
  }

}

static void MX_DMA_Init(void)
{
  /* DMA controller clock enable */
  __HAL_RCC_DMA2_CLK_ENABLE();
  __HAL_RCC_DMA1_CLK_ENABLE();

  /* DMA interrupt init */
  /* DMA1_Stream3_IRQn interrupt configuration */
  HAL_NVIC_SetPriority(DMA1_Stream3_IRQn, 5, 0);
  HAL_NVIC_EnableIRQ(DMA1_Stream3_IRQn);
  /* DMA2_Stream4_IRQn interrupt configuration */
  HAL_NVIC_SetPriority(DMA2_Stream4_IRQn, 5, 0);
  HAL_NVIC_EnableIRQ(DMA2_Stream4_IRQn);
  /* DMA2_Stream5_IRQn interrupt configuration */
  HAL_NVIC_SetPriority(DMA2_Stream5_IRQn, 5, 0);
  HAL_NVIC_EnableIRQ(DMA2_Stream5_IRQn);

}

static void MX_GPIO_Init(void)
{
  GPIO_InitTypeDef GPIO_InitStruct = {0};

  /* GPIO Ports Clock Enable */
  __HAL_RCC_GPIOE_CLK_ENABLE();
  __HAL_RCC_GPIOC_CLK_ENABLE();
  __HAL_RCC_GPIOH_CLK_ENABLE();
  __HAL_RCC_GPIOA_CLK_ENABLE();
  __HAL_RCC_GPIOB_CLK_ENABLE();
  __HAL_RCC_GPIOD_CLK_ENABLE();

  /*Configure GPIO pin Output Level */
  HAL_GPIO_WritePin(GPIOC, LEFT2_FW_Pin|LEFT2_RW_Pin|SEN3_OUT_Pin|SEN4_OUT_Pin
                          |LEFT3_FW_Pin|LEFT3_RW_Pin, GPIO_PIN_RESET);

  /*Configure GPIO pin Output Level */
  HAL_GPIO_WritePin(GPIOA, SEN1_OUT_Pin|SEN2_OUT_Pin|RIGHT1_FW_Pin|RIGHT1_RW_Pin
                          |RIGHT2_FW_Pin|RIGHT2_RW_Pin, GPIO_PIN_RESET);

  /*Configure GPIO pin Output Level */
  HAL_GPIO_WritePin(LEFT1_FW_GPIO_Port, LEFT1_FW_Pin, GPIO_PIN_RESET);

  /*Configure GPIO pin Output Level */
  HAL_GPIO_WritePin(GPIOD, LEFT1_RW_Pin|RIGHT3_FW_Pin|RIGHT3_RW_Pin|LD5_Pin
                          |LD6_Pin, GPIO_PIN_RESET);

  /*Configure GPIO pins : LEFT2_FW_Pin LEFT2_RW_Pin SEN3_OUT_Pin SEN4_OUT_Pin
                           LEFT3_FW_Pin LEFT3_RW_Pin */
  GPIO_InitStruct.Pin = LEFT2_FW_Pin|LEFT2_RW_Pin|SEN3_OUT_Pin|SEN4_OUT_Pin
                          |LEFT3_FW_Pin|LEFT3_RW_Pin;
  GPIO_InitStruct.Mode = GPIO_MODE_OUTPUT_PP;
  GPIO_InitStruct.Pull = GPIO_NOPULL;
  GPIO_InitStruct.Speed = GPIO_SPEED_FREQ_LOW;
  HAL_GPIO_Init(GPIOC, &GPIO_InitStruct);

  /*Configure GPIO pins : SEN1_OUT_Pin SEN2_OUT_Pin RIGHT1_FW_Pin RIGHT1_RW_Pin
                           RIGHT2_FW_Pin RIGHT2_RW_Pin */
  GPIO_InitStruct.Pin = SEN1_OUT_Pin|SEN2_OUT_Pin|RIGHT1_FW_Pin|RIGHT1_RW_Pin
                          |RIGHT2_FW_Pin|RIGHT2_RW_Pin;
  GPIO_InitStruct.Mode = GPIO_MODE_OUTPUT_PP;
  GPIO_InitStruct.Pull = GPIO_NOPULL;
  GPIO_InitStruct.Speed = GPIO_SPEED_FREQ_LOW;
  HAL_GPIO_Init(GPIOA, &GPIO_InitStruct);

  /*Configure GPIO pins : RIGHT1_ENC_B_Pin RIGHT2_ENC_B_Pin */
  GPIO_InitStruct.Pin = RIGHT1_ENC_B_Pin|RIGHT2_ENC_B_Pin;
  GPIO_InitStruct.Mode = GPIO_MODE_INPUT;
  GPIO_InitStruct.Pull = GPIO_PULLDOWN;
  HAL_GPIO_Init(GPIOE, &GPIO_InitStruct);

  /*Configure GPIO pins : LEFT1_ENC_B_Pin LEFT2_ENC_B_Pin LEFT3_ENC_B_Pin */
  GPIO_InitStruct.Pin = LEFT1_ENC_B_Pin|LEFT2_ENC_B_Pin|LEFT3_ENC_B_Pin;
  GPIO_InitStruct.Mode = GPIO_MODE_INPUT;
  GPIO_InitStruct.Pull = GPIO_PULLDOWN;
  HAL_GPIO_Init(GPIOB, &GPIO_InitStruct);

  /*Configure GPIO pin : LEFT1_FW_Pin */
  GPIO_InitStruct.Pin = LEFT1_FW_Pin;
  GPIO_InitStruct.Mode = GPIO_MODE_OUTPUT_PP;
  GPIO_InitStruct.Pull = GPIO_NOPULL;
  GPIO_InitStruct.Speed = GPIO_SPEED_FREQ_LOW;
  HAL_GPIO_Init(LEFT1_FW_GPIO_Port, &GPIO_InitStruct);

  /*Configure GPIO pins : SEN3_EXTI_Pin SEN4_EXTI_Pin SEN1_EXTI_Pin SEN2_EXTI_Pin */
  GPIO_InitStruct.Pin = SEN3_EXTI_Pin|SEN4_EXTI_Pin|SEN1_EXTI_Pin|SEN2_EXTI_Pin;
  GPIO_InitStruct.Mode = GPIO_MODE_IT_RISING_FALLING;
  GPIO_InitStruct.Pull = GPIO_PULLDOWN;
  HAL_GPIO_Init(GPIOD, &GPIO_InitStruct);

  /*Configure GPIO pin : RIGHT3_ENC_B_Pin */
  GPIO_InitStruct.Pin = RIGHT3_ENC_B_Pin;
  GPIO_InitStruct.Mode = GPIO_MODE_INPUT;
  GPIO_InitStruct.Pull = GPIO_PULLDOWN;
  HAL_GPIO_Init(RIGHT3_ENC_B_GPIO_Port, &GPIO_InitStruct);

  /*Configure GPIO pins : LEFT1_RW_Pin RIGHT3_FW_Pin RIGHT3_RW_Pin LD5_Pin
                           LD6_Pin */
  GPIO_InitStruct.Pin = LEFT1_RW_Pin|RIGHT3_FW_Pin|RIGHT3_RW_Pin|LD5_Pin
                          |LD6_Pin;
  GPIO_InitStruct.Mode = GPIO_MODE_OUTPUT_PP;
  GPIO_InitStruct.Pull = GPIO_NOPULL;
  GPIO_InitStruct.Speed = GPIO_SPEED_FREQ_LOW;
  HAL_GPIO_Init(GPIOD, &GPIO_InitStruct);

  /*Configure GPIO pins : LEFT1_EXTI0_Pin LEFT2_EXTI1_Pin LEFT3_EXTI2_Pin RIGHT1_EXTI3_Pin
                           RIGHT2_EXTI4_Pin RIGHT3_EXTI5_Pin */
  GPIO_InitStruct.Pin = LEFT1_EXTI0_Pin|LEFT2_EXTI1_Pin|LEFT3_EXTI2_Pin|RIGHT1_EXTI3_Pin
                          |RIGHT2_EXTI4_Pin|RIGHT3_EXTI5_Pin;
  GPIO_InitStruct.Mode = GPIO_MODE_IT_RISING;
  GPIO_InitStruct.Pull = GPIO_PULLDOWN;
  HAL_GPIO_Init(GPIOD, &GPIO_InitStruct);

  /* EXTI interrupt init*/
  HAL_NVIC_SetPriority(EXTI0_IRQn, 5, 0);
  HAL_NVIC_EnableIRQ(EXTI0_IRQn);

  HAL_NVIC_SetPriority(EXTI1_IRQn, 5, 0);
  HAL_NVIC_EnableIRQ(EXTI1_IRQn);

  HAL_NVIC_SetPriority(EXTI2_IRQn, 5, 0);
  HAL_NVIC_EnableIRQ(EXTI2_IRQn);

  HAL_NVIC_SetPriority(EXTI3_IRQn, 5, 0);
  HAL_NVIC_EnableIRQ(EXTI3_IRQn);

  HAL_NVIC_SetPriority(EXTI4_IRQn, 5, 0);
  HAL_NVIC_EnableIRQ(EXTI4_IRQn);

  HAL_NVIC_SetPriority(EXTI9_5_IRQn, 5, 0);
  HAL_NVIC_EnableIRQ(EXTI9_5_IRQn);

}

/* USER CODE BEGIN 4 */
void HAL_GPIO_EXTI_Callback(uint16_t GPIO_Pin){
  switch ( GPIO_Pin ) {
  case GPIO_PIN_0:
    if (HAL_GPIO_ReadPin(GPIOB, GPIO_PIN_12)) mot1Cntr++;
    else mot1Cntr--;
    break;
  case GPIO_PIN_1:
    if (HAL_GPIO_ReadPin(GPIOB, GPIO_PIN_13)) mot2Cntr++;
    else mot2Cntr--;
    break;
  case GPIO_PIN_2:
    if (HAL_GPIO_ReadPin(GPIOB, GPIO_PIN_14)) mot3Cntr++;
    else mot3Cntr--;
    break;
  case GPIO_PIN_3:
    if (HAL_GPIO_ReadPin(GPIOE, GPIO_PIN_7)) mot4Cntr++;
    else mot4Cntr--;
    break;
  case GPIO_PIN_4:
    if (HAL_GPIO_ReadPin(GPIOE, GPIO_PIN_8)) mot5Cntr++;
    else mot5Cntr--;
    break;
  case GPIO_PIN_5:
    if (HAL_GPIO_ReadPin(GPIOD, GPIO_PIN_10)) mot6Cntr++;
    else mot6Cntr--;
    break;
  case GPIO_PIN_6:
    sen1Cntr++;
    if (HAL_GPIO_ReadPin(GPIOD, GPIO_PIN_6)) sen1Start = TIM10->CNT;
    else {
      sen1End = TIM10->CNT;
      if (sen1End > sen1Start) sen1Length = sen1End-sen1Start;
      else sen1Length = (sen1End+65535)-sen1Start;
    }
    break;
  case GPIO_PIN_7:
    sen2Cntr++;
    if (HAL_GPIO_ReadPin(GPIOD, GPIO_PIN_7)) sen2Start = TIM10->CNT;
    else {
      sen2End = TIM10->CNT;
      if (sen2End > sen2Start) sen2Length = sen2End-sen2Start;
      else sen2Length = (sen2End+65535)-sen2Start;
    }
    break;
  case GPIO_PIN_8:
    sen3Cntr++;
    if (HAL_GPIO_ReadPin(GPIOD, GPIO_PIN_8)) sen3Start = TIM10->CNT;
    else {
      sen3End = TIM10->CNT;
      if (sen3End > sen3Start) sen3Length = sen3End-sen3Start;
      else sen3Length = (sen3End+65535)-sen3Start;
    }
    break;
  case GPIO_PIN_9:
    sen4Cntr++;
    if (HAL_GPIO_ReadPin(GPIOD, GPIO_PIN_9)) sen4Start = TIM10->CNT;
    else {
      sen4End = TIM10->CNT;
      if (sen4End > sen4Start) sen4Length = sen4End-sen4Start;
      else sen4Length = (sen4End+65535)-sen4Start;
    }
    break;
  default:
    break;
  }
}

float filter2 (float avg, float input, float alpha) {
  avg = (alpha * input) + (1.0 - alpha) * avg;
  return avg;
}

void saturateInteger(int16_t* i, int16_t min, int16_t max) {
  int16_t val = *i;
  if (val < min) val = min;
  else if (val > max) val = max;
  *i = val;
}

void saturateVolatileFloat(volatile float* i, float min, float max) {
  float val = *i;
  if (val < min) val = min;
  else if (val > max) val = max;
  *i = val;
}

void calculateLRSpeeds(float r, float phi) {

  phi = phi * PI / 180.0;

  if ((phi >= 0) && (phi < PI / 2.0)) //1st quadrant
  {
      referenceSpeedLeft = r;
      referenceSpeedRight = -r * cosf(2 * phi);
  }
  else if ((phi >= PI / 2.0) && (phi < PI)) //2nd quadrant
  {
      referenceSpeedLeft = -r * cosf(2 * phi);
      referenceSpeedRight = r;
  }
  else if ((phi >= PI) && (phi < 3 * PI / 2.0)) //3rd quadrant
  {
      referenceSpeedLeft = -r;
      referenceSpeedRight = r * cosf(2 * phi);
  }
  else if ((phi >= 3 * PI / 2.0) && (phi <= 2 * PI)) //4th quadrant
  {
      referenceSpeedLeft = r * cosf(2 * phi);
      referenceSpeedRight = -r;
  }
}

void processButtons(uint8_t buttons){
  if ((buttons & 0x01) == 0x01){
    referenceAngleL3_deg += angleIncrement;
  }
  if ((buttons & 0x04) == 0x04){
    referenceAngleL3_deg -= angleIncrement;
  }
  if ((buttons & 0x02) == 0x02){
    referenceAngleR3_deg += angleIncrement;
  }
  if ((buttons & 0x08) == 0x08){
    referenceAngleR3_deg -= angleIncrement;
  }

  if ((buttons & 0x10) == 0x10){
    autonomousActive = 1;
  }
  else {
    autonomousActive = 0;
  }

  //else{
  //  //referenceAngleL3_deg = wheelL3Angle_deg;
  //}
}
/* USER CODE END 4 */

void StartDefaultTask(void const * argument)
{

  for(;;)
  {
    osDelay(1);
  }
}

void StartSensorTask(void const * argument)
{
  /* USER CODE BEGIN StartSensorTask */
  uint32_t cycleCounter = 0;
  uint32_t targetTick;
  float compassBuffer[3];
  float accelerometerBuffer[3] = {0};

  HAL_ADC_Start_DMA(&hadc1, (uint32_t*)ADC_Buf,6);
  /* Infinite loop */
  for(;;)
  {
    //test code START
    mot1Dir = HAL_GPIO_ReadPin(GPIOB, GPIO_PIN_12);
    mot2Dir = HAL_GPIO_ReadPin(GPIOB, GPIO_PIN_13);
    mot3Dir = HAL_GPIO_ReadPin(GPIOB, GPIO_PIN_14);
    mot4Dir = HAL_GPIO_ReadPin(GPIOE, GPIO_PIN_7);
    mot5Dir = HAL_GPIO_ReadPin(GPIOE, GPIO_PIN_8);
    mot6Dir = HAL_GPIO_ReadPin(GPIOD, GPIO_PIN_10);
    internalCounter = TIM10->CNT;
    //test code END
    osDelay(speedSensingTaskCycle_ms);
    cycleCounter++;
    sen1Distance = sen1Length * 0.34/2;
    sen2Distance = sen2Length * 0.34/2;
    sen3Distance = sen3Length * 0.34/2;
    sen4Distance = sen4Length * 0.34/2;

    if (sen1Distance == sen1DistancePrev){
      sen1DebounceCounter++;
      if (sen1DebounceCounter > 1000) sen1DebounceCounter = 1000;
    }
    else {
      sen1DebounceCounter = 0;
    }

    if (sen2Distance == sen2DistancePrev){
      sen2DebounceCounter++;
      if (sen2DebounceCounter > 1000) sen2DebounceCounter = 1000;
    }
    else {
      sen2DebounceCounter = 0;
    }

    if (sen3Distance == sen3DistancePrev){
      sen3DebounceCounter++;
      if (sen3DebounceCounter > 1000) sen3DebounceCounter = 1000;
    }
    else {
      sen3DebounceCounter = 0;
    }

    if (sen4Distance == sen4DistancePrev){
      sen4DebounceCounter++;
      if (sen4DebounceCounter > 1000) sen4DebounceCounter = 1000;
    }
    else {
      sen4DebounceCounter = 0;
    }

    sen1DistancePrev = sen1Distance;
    sen2DistancePrev = sen2Distance;
    sen3DistancePrev = sen3Distance;
    sen4DistancePrev = sen4Distance;

    sen1DistanceFiltered = filter2(sen1DistanceFiltered, sen1Distance, 0.2);
    sen2DistanceFiltered = filter2(sen2DistanceFiltered, sen2Distance, 0.2);
    sen3DistanceFiltered = filter2(sen3DistanceFiltered, sen3Distance, 0.2);
    sen4DistanceFiltered = filter2(sen4DistanceFiltered, sen4Distance, 0.2);

    batteryVoltage1 = ADC_Values[0]*3.0*10/4095;
    batteryVoltage2 = ADC_Values[1]*3.0*10/4095;
    sen1AnalogValue = ADC_Values[2];
    sen2AnalogValue = ADC_Values[3];
    sen3AnalogValue = ADC_Values[4];
    sen4AnalogValue = ADC_Values[5];

    if ((mot1Cntr - mot1CntrPrev) > 32000){
      wheelL1Odometer_m += (mot1Cntr - 65535 - mot1CntrPrev) * wheelSize_m / encoderSignalsPerRound;
      wheelL1Angle_deg += (mot1Cntr - 65535 - mot1CntrPrev) * 360.0 / encoderSignalsPerRound;
    }
    else if ((mot1Cntr - mot1CntrPrev) < -32000){
      wheelL1Odometer_m += (mot1Cntr + 65535 - mot1CntrPrev) * wheelSize_m / encoderSignalsPerRound;
      wheelL1Angle_deg += (mot1Cntr + 65535 - mot1CntrPrev) * 360.0 / encoderSignalsPerRound;
    }
    else {
      wheelL1Odometer_m += (mot1Cntr - mot1CntrPrev) * wheelSize_m / encoderSignalsPerRound;
      wheelL1Angle_deg += (mot1Cntr - mot1CntrPrev) * 360.0 / encoderSignalsPerRound;
    }

    if ((mot2Cntr - mot2CntrPrev) > 32000){
      wheelL2Odometer_m += (mot2Cntr - 65535 - mot2CntrPrev) * wheelSize_m / encoderSignalsPerRound;
      wheelL2Angle_deg += (mot2Cntr - 65535 - mot2CntrPrev) * 360.0 / encoderSignalsPerRound;
    }
    else if ((mot2Cntr - mot2CntrPrev) < -32000){
      wheelL2Odometer_m += (mot2Cntr + 65535 - mot2CntrPrev) * wheelSize_m / encoderSignalsPerRound;
      wheelL2Angle_deg += (mot2Cntr + 65535 - mot2CntrPrev) * 360.0 / encoderSignalsPerRound;
    }
    else {
      wheelL2Odometer_m += (mot2Cntr - mot2CntrPrev) * wheelSize_m / encoderSignalsPerRound;
      wheelL2Angle_deg += (mot2Cntr - mot2CntrPrev) * 360.0 / encoderSignalsPerRound;
    }

    if ((mot3Cntr - mot3CntrPrev) > 32000){
      wheelL3Odometer_m += (mot3Cntr - 65535 - mot3CntrPrev) * wheelSize_m / encoderSignalsPerRound;
      wheelL3Angle_deg += (mot3Cntr - 65535 - mot3CntrPrev) * 360.0 / encoderSignalsPerRound;
    }
    else if ((mot3Cntr - mot3CntrPrev) < -32000){
      wheelL3Odometer_m += (mot3Cntr + 65535 - mot3CntrPrev) * wheelSize_m / encoderSignalsPerRound;
      wheelL3Angle_deg += (mot3Cntr + 65535 - mot3CntrPrev) * 360.0 / encoderSignalsPerRound;
    }
    else {
      wheelL3Odometer_m += (mot3Cntr - mot3CntrPrev) * wheelSize_m / encoderSignalsPerRound;
      wheelL3Angle_deg += (mot3Cntr - mot3CntrPrev) * 360.0 / encoderSignalsPerRound;
    }

    if ((mot4Cntr - mot4CntrPrev) > 32000){
      wheelR1Odometer_m += (mot4Cntr - 65535 - mot4CntrPrev) * wheelSize_m / encoderSignalsPerRound;
      wheelR1Angle_deg += (mot4Cntr - 65535 - mot4CntrPrev) * 360.0 / encoderSignalsPerRound;
    }
    else if ((mot4Cntr - mot4CntrPrev) < -32000){
      wheelR1Odometer_m += (mot4Cntr + 65535 - mot4CntrPrev) * wheelSize_m / encoderSignalsPerRound;
      wheelR1Angle_deg += (mot4Cntr + 65535 - mot4CntrPrev) * 360.0 / encoderSignalsPerRound;
    }
    else {
      wheelR1Odometer_m += (mot4Cntr - mot4CntrPrev) * wheelSize_m / encoderSignalsPerRound;
      wheelR1Angle_deg += (mot4Cntr - mot4CntrPrev) * 360.0 / encoderSignalsPerRound;
    }

    if ((mot5Cntr - mot5CntrPrev) > 32000){
      wheelR2Odometer_m += (mot5Cntr - 65535 - mot5CntrPrev) * wheelSize_m / encoderSignalsPerRound;
      wheelR2Angle_deg += (mot5Cntr - 65535 - mot5CntrPrev) * 360.0 / encoderSignalsPerRound;
    }
    else if ((mot5Cntr - mot5CntrPrev) < -32000){
      wheelR2Odometer_m += (mot5Cntr + 65535 - mot5CntrPrev) * wheelSize_m / encoderSignalsPerRound;
      wheelR2Angle_deg += (mot5Cntr + 65535 - mot5CntrPrev) * 360.0 / encoderSignalsPerRound;
    }
    else {
      wheelR2Odometer_m += (mot5Cntr - mot5CntrPrev) * wheelSize_m / encoderSignalsPerRound;
      wheelR2Angle_deg += (mot5Cntr - mot5CntrPrev) * 360.0 / encoderSignalsPerRound;
    }

    if ((mot6Cntr - mot6CntrPrev) > 32000){
      wheelR3Odometer_m += (mot6Cntr - 65535 - mot6CntrPrev) * wheelSize_m / encoderSignalsPerRound;
      wheelR3Angle_deg += (mot6Cntr - 65535 - mot6CntrPrev) * 360.0 / encoderSignalsPerRound;
    }
    else if ((mot6Cntr - mot6CntrPrev) < -32000){
      wheelR3Odometer_m += (mot6Cntr + 65535 - mot6CntrPrev) * wheelSize_m / encoderSignalsPerRound;
      wheelR3Angle_deg += (mot6Cntr + 65535 - mot6CntrPrev) * 360.0 / encoderSignalsPerRound;
    }
    else {
      wheelR3Odometer_m += (mot6Cntr - mot6CntrPrev) * wheelSize_m / encoderSignalsPerRound;
      wheelR3Angle_deg += (mot6Cntr - mot6CntrPrev) * 360.0 / encoderSignalsPerRound;
    }

    wheelL1RawVelocity_mps = (wheelL1Odometer_m - wheelL1Odometer_m_prev) * 1000.0 / speedSensingTaskCycle_ms;
    wheelL2RawVelocity_mps = (wheelL2Odometer_m - wheelL2Odometer_m_prev) * 1000.0 / speedSensingTaskCycle_ms;
    wheelL3RawVelocity_mps = (wheelL3Odometer_m - wheelL3Odometer_m_prev) * 1000.0 / speedSensingTaskCycle_ms;
    wheelR1RawVelocity_mps = (wheelR1Odometer_m - wheelR1Odometer_m_prev) * 1000.0 / speedSensingTaskCycle_ms;
    wheelR2RawVelocity_mps = (wheelR2Odometer_m - wheelR2Odometer_m_prev) * 1000.0 / speedSensingTaskCycle_ms;
    wheelR3RawVelocity_mps = (wheelR3Odometer_m - wheelR3Odometer_m_prev) * 1000.0 / speedSensingTaskCycle_ms;

    wheelL1FiltVelocity_mps = filter2(wheelL1FiltVelocity_mps, wheelL1RawVelocity_mps, 0.35);
    wheelL2FiltVelocity_mps = filter2(wheelL2FiltVelocity_mps, wheelL2RawVelocity_mps, 0.35);
    wheelL3FiltVelocity_mps = filter2(wheelL3FiltVelocity_mps, wheelL3RawVelocity_mps, 0.35);
    wheelR1FiltVelocity_mps = filter2(wheelR1FiltVelocity_mps, wheelR1RawVelocity_mps, 0.35);
    wheelR2FiltVelocity_mps = filter2(wheelR2FiltVelocity_mps, wheelR2RawVelocity_mps, 0.35);
    wheelR3FiltVelocity_mps = filter2(wheelR3FiltVelocity_mps, wheelR3RawVelocity_mps, 0.35);

    wheelL1FiltVelocity_rpm = wheelL1FiltVelocity_mps / wheelSize_m * 360 / 6;
    wheelL2FiltVelocity_rpm = wheelL2FiltVelocity_mps / wheelSize_m * 360 / 6;
    wheelL3FiltVelocity_rpm = wheelL3FiltVelocity_mps / wheelSize_m * 360 / 6;
    wheelR1FiltVelocity_rpm = wheelR1FiltVelocity_mps / wheelSize_m * 360 / 6;
    wheelR2FiltVelocity_rpm = wheelR2FiltVelocity_mps / wheelSize_m * 360 / 6;
    wheelR3FiltVelocity_rpm = wheelR3FiltVelocity_mps / wheelSize_m * 360 / 6;

    wheelL1Odometer_m_prev = wheelL1Odometer_m;
    wheelL2Odometer_m_prev = wheelL2Odometer_m;
    wheelL3Odometer_m_prev = wheelL3Odometer_m;
    wheelR1Odometer_m_prev = wheelR1Odometer_m;
    wheelR2Odometer_m_prev = wheelR2Odometer_m;
    wheelR3Odometer_m_prev = wheelR3Odometer_m;
    mot1CntrPrev = mot1Cntr;
    mot2CntrPrev = mot2Cntr;
    mot3CntrPrev = mot3Cntr;
    mot4CntrPrev = mot4Cntr;
    mot5CntrPrev = mot5Cntr;
    mot6CntrPrev = mot6Cntr;

    if (cycleCounter % 10 == 0){
      if (TIM10->CNT < 65534){
        HAL_GPIO_WritePin(GPIOA, GPIO_PIN_4, GPIO_PIN_SET); //SEN1 trigger
        targetTick = TIM10->CNT+1;
        while (TIM10->CNT <= targetTick);
        HAL_GPIO_WritePin(GPIOA, GPIO_PIN_4, GPIO_PIN_RESET); //SEN1 trigger
      }
    }

    if (cycleCounter % 10 == 2){
      if (TIM10->CNT < 65534){
        HAL_GPIO_WritePin(GPIOA, GPIO_PIN_5, GPIO_PIN_SET); //SEN2 trigger
        targetTick = TIM10->CNT+1;
        while (TIM10->CNT <= targetTick);
        HAL_GPIO_WritePin(GPIOA, GPIO_PIN_5, GPIO_PIN_RESET); //SEN2 trigger
      }
    }

    if (cycleCounter % 10 == 4){
      if (TIM10->CNT < 65534){
        HAL_GPIO_WritePin(GPIOC, GPIO_PIN_4, GPIO_PIN_SET); //SEN3 trigger
        targetTick = TIM10->CNT+1;
        while (TIM10->CNT <= targetTick);
        HAL_GPIO_WritePin(GPIOC, GPIO_PIN_4, GPIO_PIN_RESET); //SEN3 trigger
      }
    }

    if (cycleCounter % 10 == 6){
      if (TIM10->CNT < 65534){
        HAL_GPIO_WritePin(GPIOC, GPIO_PIN_5, GPIO_PIN_SET); //SEN4 trigger
        targetTick = TIM10->CNT+1;
        while (TIM10->CNT <= targetTick);
        HAL_GPIO_WritePin(GPIOC, GPIO_PIN_5, GPIO_PIN_RESET); //SEN4 trigger
      }
    }

    if (cycleCounter % 4 == 0){
      /* Read Acceleration*/
      BSP_ACCELERO_GetXYZ(accelerometerBuffer);

      accX = accelerometerBuffer[0];
      accY = accelerometerBuffer[1];
      accZ = accelerometerBuffer[2];

      accXFiltered = filter2(accXFiltered, accX, 0.2);
      accYFiltered = filter2(accYFiltered, accY, 0.2);
      accZFiltered = filter2(accZFiltered, accZ, 0.2);

      fNormAcc = sqrt((accXFiltered*accXFiltered)+(accYFiltered*accYFiltered)+(accZFiltered*accZFiltered));

      fSinRoll = accYFiltered/fNormAcc;
      fCosRoll = sqrt(1.0-(fSinRoll * fSinRoll));
      fSinPitch = accXFiltered/fNormAcc;
      fCosPitch = sqrt(1.0-(fSinPitch * fSinPitch));

      if ( fSinRoll >0) {
        if (fCosRoll>0) roll = acos(fCosRoll)*180/PI;
        else            roll = acos(fCosRoll)*180/PI + 180;
      }
      else {
        if (fCosRoll>0) roll = acos(fCosRoll)*180/PI + 360;
        else            roll = acos(fCosRoll)*180/PI + 180;
      }

      if ( fSinPitch >0) {
        if (fCosPitch>0) pitch = acos(fCosPitch)*180/PI;
        else             pitch = acos(fCosPitch)*180/PI + 180;
      }
      else {
        if (fCosPitch>0) pitch = acos(fCosPitch)*180/PI + 360;
        else             pitch = acos(fCosPitch)*180/PI + 180;
      }

      if (roll >=360)  roll = 360 - roll;
      if (pitch >=360) pitch = 360 - pitch;

      /* Read Magnetometer*/
      LSM303DLHC_MagReadXYZ(compassBuffer);
      compassX = compassBuffer[0];
      compassY = compassBuffer[1];
      compassZ = compassBuffer[2];
    }
  }
  /* USER CODE END StartSensorTask */
}

void StartControlTask(void const * argument)
{
  /* USER CODE BEGIN StartControlTask */
  /* Infinite loop */
  for(;;)
  {

    reqSpeedLeft = -referenceSpeedLeft;
    reqSpeedRight = referenceSpeedRight;

    if (reqSpeedLeft > currSpeedLeft){
      if (reqSpeedLeft > currSpeedLeft + speedRampRate){
        nextSpeedLeft = currSpeedLeft + speedRampRate;
      }
      else{
        nextSpeedLeft = reqSpeedLeft;
      }
    }
    else if (reqSpeedLeft < currSpeedLeft){
      if (reqSpeedLeft < currSpeedLeft - speedRampRate){
        nextSpeedLeft = currSpeedLeft - speedRampRate;
      }
      else{
        nextSpeedLeft = reqSpeedLeft;
      }
    }

    if (reqSpeedRight > currSpeedRight){
      if (reqSpeedRight > currSpeedRight + speedRampRate){
        nextSpeedRight = currSpeedRight + speedRampRate;
      }
      else{
        nextSpeedRight = reqSpeedRight;
      }
    }
    else if (reqSpeedRight < currSpeedRight){
      if (reqSpeedRight < currSpeedRight - speedRampRate){
        nextSpeedRight = currSpeedRight - speedRampRate;
      }
      else{
        nextSpeedRight = reqSpeedRight;
      }
    }

    wheelL1VelocityErrorBefore = wheelL1VelocityError;
    wheelL1VelocityError = nextSpeedLeft - wheelL1FiltVelocity_mps;
    wheelL1VelocityIntError = wheelL1VelocityIntError + wheelL1VelocityError + antiWindup * (wheelL1SumControl - wheelL1SumControlBeforeSaturation);
    wheelL1VelocityDerivatedError = wheelL1VelocityError - wheelL1VelocityErrorBefore;
    wheelL1SumControl = (int)(ctrlP * wheelL1VelocityError + ctrlI * wheelL1VelocityIntError + ctrlD * wheelL1VelocityDerivatedError);
    wheelL1SumControlBeforeSaturation = wheelL1SumControl;

    wheelL2VelocityErrorBefore = wheelL2VelocityError;
    wheelL2VelocityError = nextSpeedLeft - wheelL2FiltVelocity_mps;
    wheelL2VelocityIntError = wheelL2VelocityIntError + wheelL2VelocityError + antiWindup * (wheelL2SumControl - wheelL2SumControlBeforeSaturation);
    wheelL2VelocityDerivatedError = wheelL2VelocityError - wheelL2VelocityErrorBefore;
    wheelL2SumControl = (int)(ctrlP * wheelL2VelocityError + ctrlI * wheelL2VelocityIntError + ctrlD * wheelL2VelocityDerivatedError);
    wheelL2SumControlBeforeSaturation = wheelL2SumControl;

    positionErrorL3_deg = referenceAngleL3_deg - wheelL3Angle_deg;

    wheelL3VelocityErrorBefore = wheelL3VelocityError;
    wheelL3VelocityError = (positionErrorL3_deg * ctrlP_pos) - wheelL3FiltVelocity_mps;
    wheelL3VelocityIntError = wheelL3VelocityIntError + wheelL3VelocityError + antiWindup * (wheelL3SumControl - wheelL3SumControlBeforeSaturation);
    wheelL3VelocityDerivatedError = wheelL3VelocityError - wheelL3VelocityErrorBefore;
    wheelL3SumControl = (int)(ctrlP * wheelL3VelocityError + ctrlI * wheelL3VelocityIntError + ctrlD * wheelL3VelocityDerivatedError);
    wheelL3SumControlBeforeSaturation = wheelL3SumControl;

    wheelR1VelocityErrorBefore = wheelR1VelocityError;
    wheelR1VelocityError = nextSpeedRight - wheelR1FiltVelocity_mps;
    wheelR1VelocityIntError = wheelR1VelocityIntError + wheelR1VelocityError + antiWindup * (wheelR1SumControl - wheelR1SumControlBeforeSaturation);
    wheelR1VelocityDerivatedError = wheelR1VelocityError - wheelR1VelocityErrorBefore;
    wheelR1SumControl = (int)(ctrlP * wheelR1VelocityError + ctrlI * wheelR1VelocityIntError + ctrlD * wheelR1VelocityDerivatedError);
    wheelR1SumControlBeforeSaturation = wheelR1SumControl;

    wheelR2VelocityErrorBefore = wheelR2VelocityError;
    wheelR2VelocityError = nextSpeedRight - wheelR2FiltVelocity_mps;
    wheelR2VelocityIntError = wheelR2VelocityIntError + wheelR2VelocityError + antiWindup * (wheelR2SumControl - wheelR2SumControlBeforeSaturation);
    wheelR2VelocityDerivatedError = wheelR2VelocityError - wheelR2VelocityErrorBefore;
    wheelR2SumControl = (int)(ctrlP * wheelR2VelocityError + ctrlI * wheelR2VelocityIntError + ctrlD * wheelR2VelocityDerivatedError);
    wheelR2SumControlBeforeSaturation = wheelR2SumControl;

    positionErrorR3_deg = referenceAngleR3_deg - wheelR3Angle_deg;

    wheelR3VelocityErrorBefore = wheelR3VelocityError;
    wheelR3VelocityError = (positionErrorR3_deg * ctrlP_pos) - wheelR3FiltVelocity_mps;
    wheelR3VelocityIntError = wheelR3VelocityIntError + wheelR3VelocityError + antiWindup * (wheelR3SumControl - wheelR3SumControlBeforeSaturation);
    wheelR3VelocityDerivatedError = wheelR3VelocityError - wheelR3VelocityErrorBefore;
    wheelR3SumControl = (int)(ctrlP * wheelR3VelocityError + ctrlI * wheelR3VelocityIntError + ctrlD * wheelR3VelocityDerivatedError);
    wheelR3SumControlBeforeSaturation = wheelR3SumControl;

    if (fabs(nextSpeedLeft) < 0.01) {
      wheelL1VelocityIntError -= wheelL1VelocityIntError*0.01;
      wheelL2VelocityIntError -= wheelL2VelocityIntError*0.01;
      wheelL3VelocityIntError -= wheelL3VelocityIntError*0.01;
    }
    if (fabs(nextSpeedRight) < 0.01) {
      wheelR1VelocityIntError -= wheelR1VelocityIntError*0.01;
      wheelR2VelocityIntError -= wheelR2VelocityIntError*0.01;
      wheelR3VelocityIntError -= wheelR3VelocityIntError*0.01;
    }

    saturateVolatileFloat(&wheelL1SumControl, -maxDutyCycle, maxDutyCycle);
    saturateVolatileFloat(&wheelL2SumControl, -maxDutyCycle, maxDutyCycle);
    saturateVolatileFloat(&wheelL3SumControl, -maxDutyCycle, maxDutyCycle);
    saturateVolatileFloat(&wheelR1SumControl, -maxDutyCycle, maxDutyCycle);
    saturateVolatileFloat(&wheelR2SumControl, -maxDutyCycle, maxDutyCycle);
    saturateVolatileFloat(&wheelR3SumControl, -maxDutyCycle, maxDutyCycle);

    if (wheelL1SumControl>=0){
      HAL_GPIO_WritePin(GPIOB, GPIO_PIN_15, GPIO_PIN_SET); //LEFT1 FW
      HAL_GPIO_WritePin(GPIOD, GPIO_PIN_11, GPIO_PIN_RESET); //LEFT1 RW
    }
    else {
      HAL_GPIO_WritePin(GPIOB, GPIO_PIN_15, GPIO_PIN_RESET); //LEFT1 FW
      HAL_GPIO_WritePin(GPIOD, GPIO_PIN_11, GPIO_PIN_SET); //LEFT1 RW
    }
    TIM1->CCR1 = abs((int)wheelL1SumControl)*4800/100; //LEFT1

    if (wheelL2SumControl>=0){
      HAL_GPIO_WritePin(GPIOC, GPIO_PIN_13, GPIO_PIN_SET); //LEFT2 FW
      HAL_GPIO_WritePin(GPIOC, GPIO_PIN_14, GPIO_PIN_RESET); //LEFT2 RW
    }
    else {
      HAL_GPIO_WritePin(GPIOC, GPIO_PIN_13, GPIO_PIN_RESET); //LEFT2 FW
      HAL_GPIO_WritePin(GPIOC, GPIO_PIN_14, GPIO_PIN_SET); //LEFT2 RW
    }
    TIM1->CCR2 = abs((int)wheelL2SumControl)*4800/100; //LEFT2

    if (wheelL3SumControl>=0){
      HAL_GPIO_WritePin(GPIOC, GPIO_PIN_10, GPIO_PIN_SET); //LEFT3 FW
      HAL_GPIO_WritePin(GPIOC, GPIO_PIN_11, GPIO_PIN_RESET); //LEFT3 RW
    }
    else {
      HAL_GPIO_WritePin(GPIOC, GPIO_PIN_10, GPIO_PIN_RESET); //LEFT3 FW
      HAL_GPIO_WritePin(GPIOC, GPIO_PIN_11, GPIO_PIN_SET); //LEFT3 RW
    }
    TIM1->CCR3 = abs((int)wheelL3SumControl)*4800/100; //LEFT3

    if (wheelR1SumControl>=0){
      HAL_GPIO_WritePin(GPIOA, GPIO_PIN_6,  GPIO_PIN_SET); //RIGHT1 FW
      HAL_GPIO_WritePin(GPIOA, GPIO_PIN_7,  GPIO_PIN_RESET); //RIGHT1 RW
    }
    else {
      HAL_GPIO_WritePin(GPIOA, GPIO_PIN_6,  GPIO_PIN_RESET); //RIGHT1 FW
      HAL_GPIO_WritePin(GPIOA, GPIO_PIN_7,  GPIO_PIN_SET); //RIGHT1 RW
    }
    TIM1->CCR4 = abs((int)wheelR1SumControl)*4800/100; //RIGHT1

    if (wheelR2SumControl>=0){
      HAL_GPIO_WritePin(GPIOA, GPIO_PIN_9,  GPIO_PIN_SET); //RIGHT2 FW
      HAL_GPIO_WritePin(GPIOA, GPIO_PIN_10, GPIO_PIN_RESET); //RIGHT2 RW
    }
    else {
      HAL_GPIO_WritePin(GPIOA, GPIO_PIN_9,  GPIO_PIN_RESET); //RIGHT2 FW
      HAL_GPIO_WritePin(GPIOA, GPIO_PIN_10, GPIO_PIN_SET); //RIGHT2 RW
    }
    TIM2->CCR1 = abs((int)wheelR2SumControl)*4800/100; //RIGHT2

    if (wheelR3SumControl>=0){
      HAL_GPIO_WritePin(GPIOD, GPIO_PIN_12, GPIO_PIN_SET); //RIGHT3 FW
      HAL_GPIO_WritePin(GPIOD, GPIO_PIN_13, GPIO_PIN_RESET); //RIGHT3 RW
    }
    else {
      HAL_GPIO_WritePin(GPIOD, GPIO_PIN_12, GPIO_PIN_RESET); //RIGHT3 FW
      HAL_GPIO_WritePin(GPIOD, GPIO_PIN_13, GPIO_PIN_SET); //RIGHT3 RW
    }
    TIM2->CCR3 = abs((int)wheelR3SumControl)*4800/100; //RIGHT3

    currSpeedLeft = nextSpeedLeft;
    currSpeedRight = nextSpeedRight;

    osDelay(20);
  }
  /* USER CODE END StartControlTask */
}

void StartCommTask(void const * argument)
{
  /* USER CODE BEGIN StartCommTask */
  /* Infinite loop */
  for(;;)
  {
    HAL_UART_Receive_IT(&huart6,receiveBuffer,5);

    if ((receiveBuffer[0] == 0xFF) && (receiveBuffer[1] <=100) && (receiveBuffer[2] <=180)){
      //referenceSpeedOrig = receiveBuffer[1] / 10.0;
      //referenceSpeed = calcSpdRef_LUT(referenceSpeedOrig);
      referenceSpeed = receiveBuffer[1] / (100 / maxVelocity);
      referenceAngle = receiveBuffer[2] * 2.0;
      buttonState = receiveBuffer[3];
      messageCounter = receiveBuffer[4];
      if (messageCounter != messageCounterPrev){
        timeStamp = HAL_GetTick();
        messageCounterPrev = messageCounter;
      }
    }

    timeOutGuard = HAL_GetTick() - timeStamp;
    if (timeOutGuard > timeOutGuardMax){
      timeOutGuardMax = timeOutGuard;
    }

    if ((timeOutGuard) > 1000){
      referenceSpeed = 0;
      referenceAngle = 0;
      buttonState = 0;
    }

    osDelay(20);
  }
  /* USER CODE END StartCommTask */
}

void StartIdleTask(void const * argument)
{
  /* USER CODE BEGIN StartIdleTask */
  /* Infinite loop */
  for(;;)
  {
    osDelay(1000);
    HAL_GPIO_TogglePin(GPIOD, GPIO_PIN_15);
  }
  /* USER CODE END StartIdleTask */
}

void StartLedTask(void const * argument)
{
  /* USER CODE BEGIN StartLedTask */
  uint8_t cycleCounter=0;
  uint32_t roundCounter = 0;
  int8_t bluetoothBlinkCounter = 0;
  int8_t battery1BlinkCounter = 0;
  int8_t battery2BlinkCounter = 0;

  float voltageFullRange_Mot = NORMALVOLTAGE_MOT - LOWVOLTAGE_MOT;
  float voltageFullRange_Logic = NORMALVOLTAGE_LOGIC - LOWVOLTAGE_LOGIC;
  float voltageInRange = 0;
  float voltageRatio = 0;
  float cellVoltage = 0;

  WS2812_One_RGB(0,(WS2812_RGB_t){0,10,0},0);
  WS2812_One_RGB(1,(WS2812_RGB_t){10,10,10},0);
  WS2812_One_RGB(2,(WS2812_RGB_t){10,0,0},0);
  WS2812_One_RGB(3,(WS2812_RGB_t){10,10,0},0);
  WS2812_One_RGB(4,(WS2812_RGB_t){0,0,10},1);
  /* Infinite loop */
  for(;;)
  {
    osDelay(150);
    cycleCounter++;
    HAL_GPIO_TogglePin(GPIOD, GPIO_PIN_14);

    if (bumperActive){
      WS2812_All_RGB((WS2812_RGB_t){10,0,0},0);
    }
    else if (ultrasonicActive){
      WS2812_All_RGB((WS2812_RGB_t){0,10,0},0);
    }
    else {
      WS2812_All_RGB((WS2812_RGB_t){0,0,0},0);
      WS2812_One_RGB(((roundCounter%12)+4),(WS2812_RGB_t){0,0,10},0);
      roundCounter++;
      WS2812_Revvy_Shift_Right(0);
    }

    WS2812_One_RGB(0,(WS2812_RGB_t){30,30,30},0);

    if ((timeOutGuard) > 1000){
      if ((bluetoothBlinkCounter >= 0) && (bluetoothBlinkCounter < 3)) WS2812_One_RGB(1,(WS2812_RGB_t){0,0,30},0);
      else if ((bluetoothBlinkCounter >= 3) && (bluetoothBlinkCounter < 7)) WS2812_One_RGB(1,(WS2812_RGB_t){0,0,0},0);
      if (bluetoothBlinkCounter == 6) bluetoothBlinkCounter = -1;
      bluetoothBlinkCounter++;
    }
    else{
      WS2812_One_RGB(1,(WS2812_RGB_t){0,0,30},0);
    }

    cellVoltage = batteryVoltage1 / 4;
    if (cellVoltage >= NORMALVOLTAGE_LOGIC){
      WS2812_One_RGB(2,(WS2812_RGB_t){0,30,0},0);
    }
    else if ((cellVoltage < NORMALVOLTAGE_LOGIC) && (cellVoltage >= LOWVOLTAGE_LOGIC)){
      voltageInRange = cellVoltage - LOWVOLTAGE_LOGIC;
      voltageRatio = voltageInRange / voltageFullRange_Logic;
      WS2812_One_RGB(2,(WS2812_RGB_t){(int)(30*(1-voltageRatio)),(int)(30*(voltageRatio)),0},0);
    }
    else if (cellVoltage < LOWVOLTAGE_LOGIC){
      if (battery1BlinkCounter == 0) WS2812_One_RGB(2,(WS2812_RGB_t){30,0,0},0);
      else if (battery1BlinkCounter == 2) WS2812_One_RGB(2,(WS2812_RGB_t){0,0,0},0);
      else if (battery1BlinkCounter == 4) battery1BlinkCounter = -1;
      battery1BlinkCounter++;
    }
    else {
      WS2812_One_RGB(2,(WS2812_RGB_t){30,30,30},0);
    }

    cellVoltage = batteryVoltage2 / 4;
    if (cellVoltage >= NORMALVOLTAGE_MOT){
      WS2812_One_RGB(3,(WS2812_RGB_t){0,30,0},0);
    }
    else if ((cellVoltage < NORMALVOLTAGE_MOT) && (cellVoltage >= LOWVOLTAGE_MOT)){
      voltageInRange = cellVoltage - LOWVOLTAGE_MOT;
      voltageRatio = voltageInRange / voltageFullRange_Mot;
      WS2812_One_RGB(3,(WS2812_RGB_t){(int)(30*(1-voltageRatio)),(int)(30*(voltageRatio)),0},0);
    }
    else if (cellVoltage < LOWVOLTAGE_MOT){
      if (battery2BlinkCounter == 0) WS2812_One_RGB(3,(WS2812_RGB_t){30,0,0},0);
      else if (battery2BlinkCounter == 2) WS2812_One_RGB(3,(WS2812_RGB_t){0,0,0},0);
      else if (battery2BlinkCounter == 4) battery2BlinkCounter = -1;
      battery2BlinkCounter++;
    }
    else {
      WS2812_One_RGB(3,(WS2812_RGB_t){30,30,30},0);
    }

    WS2812_Refresh();
    HAL_GPIO_TogglePin(GPIOD, GPIO_PIN_14);

  }
  /* USER CODE END StartLedTask */
}

void StartApplicationTask(void const * argument)
{
  /* USER CODE BEGIN StartApplicationTask */
  /* Infinite loop */
  for(;;)
  {
    if (autonomousActive){
      referenceAngle = 90;
      referenceSpeed = 0.2;
    }

    if (((sen1DistanceFiltered < 20) && (sen1DebounceCounter < ultrasonicDebounceLimit)) || ((sen2DistanceFiltered < 20) && (sen2DebounceCounter < ultrasonicDebounceLimit)) || ((sen3DistanceFiltered < 20) && (sen3DebounceCounter < ultrasonicDebounceLimit)) || ((sen4DistanceFiltered < 20) && (sen4DebounceCounter < ultrasonicDebounceLimit))){
      ultrasonicActive = 1;
      referenceAngle = 180;
      referenceSpeed = 0.1;
    }
    else {
      ultrasonicActive = 0;
    }

    if ((sen1AnalogValue > 100) || (sen2AnalogValue > 100) || (sen3AnalogValue > 100) || (sen4AnalogValue > 100)){
      bumperActive = 1;
      referenceAngle = 90;
      referenceSpeed = 0.2;
    }
    else {
      bumperActive = 0;
    }

    calculateLRSpeeds(referenceSpeed, referenceAngle);
    processButtons(buttonState);

    osDelay(10);
  }
  /* USER CODE END StartApplicationTask */
}

void HAL_TIM_PeriodElapsedCallback(TIM_HandleTypeDef *htim)
{
  if (htim->Instance == TIM11) {
    HAL_IncTick();
  }
}

void Error_Handler(void)
{
  while(1)
  {
  }
}

#ifdef  USE_FULL_ASSERT
/**
  * @brief  Reports the name of the source file and the source line number
  *         where the assert_param error has occurred.
  * @param  file: pointer to the source file name
  * @param  line: assert_param error line source number
  * @retval None
  */
void assert_failed(uint8_t *file, uint32_t line)
{
  /* USER CODE BEGIN 6 */
  /* User can add his own implementation to report the file name and line number,
     tex: printf("Wrong parameters value: file %s on line %d\r\n", file, line) */
  while(1);
  /* USER CODE END 6 */
}
#endif /* USE_FULL_ASSERT */

/************************ (C) COPYRIGHT STMicroelectronics *****END OF FILE****/
